AUTOSAR XML (schema 4-3-0)
package /ComponentTypes
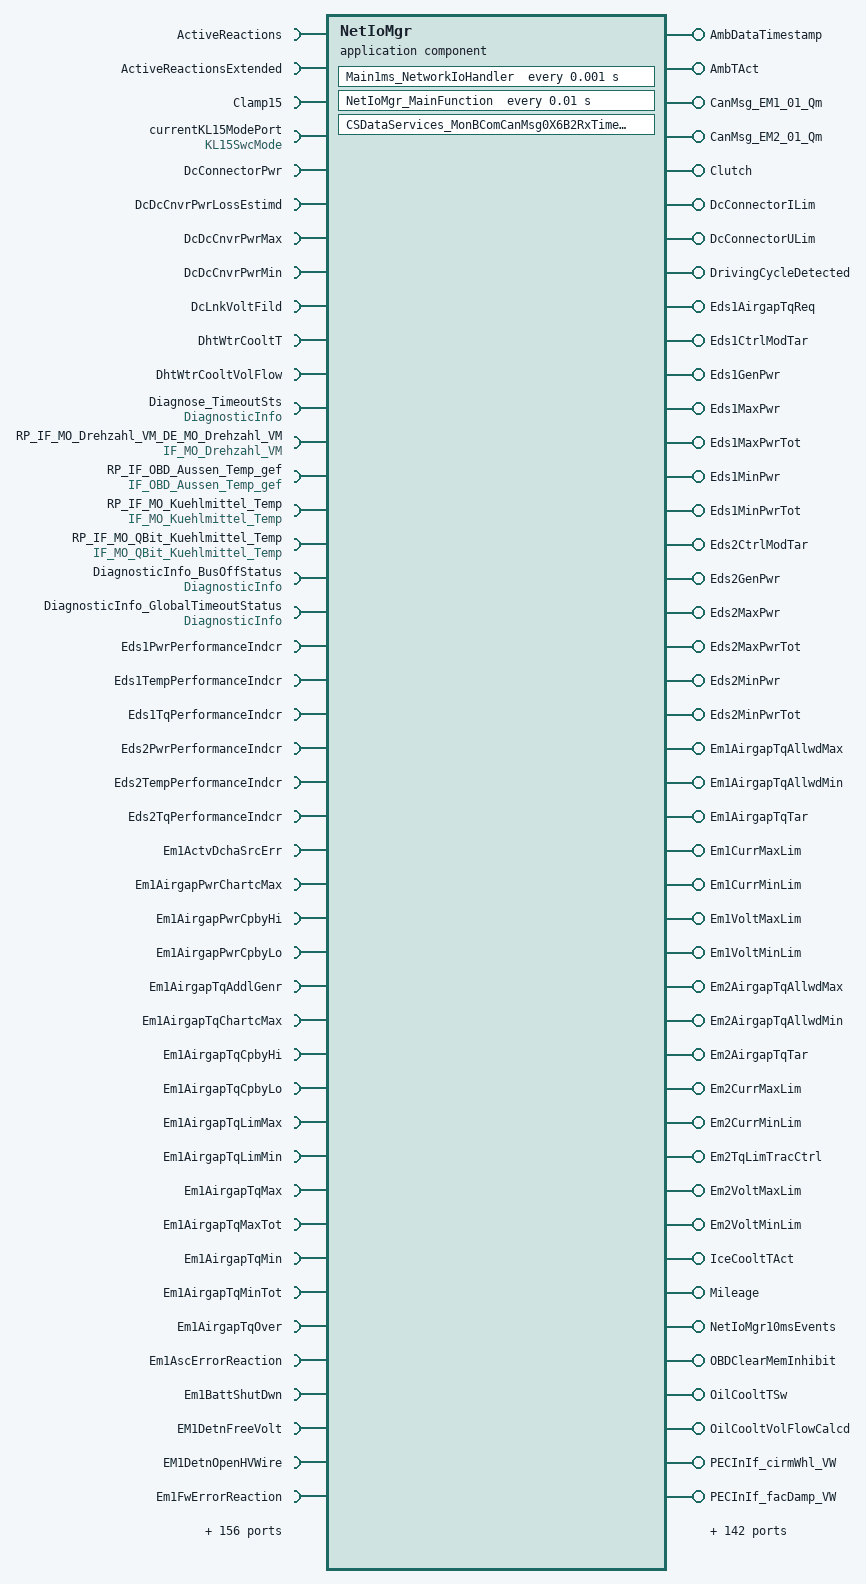
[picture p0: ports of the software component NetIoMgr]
  application sw component type NetIoMgr
    require port ActiveReactions: nonqueued-receiver-com-spec{data-element=Status, filter=data-filter-type=ALWAYS, init-value=0}, required-interface=ActiveReactions
    require port ActiveReactionsExtended: nonqueued-receiver-com-spec{data-element=Status, filter=data-filter-type=ALWAYS}, required-interface=ActiveReactionsExtended
    4 x provide port:
      AmbDataTimestamp: nonqueued-sender-com-spec{data-element=Val, init-value=fields=[UH_Jahr:0, UH_Monat:0, UH_Tag:0, UH_Stunde:0, UH_Minute:0, UH_Sekunde:0]}, provided-interface=AmbDataTimestamp
      AmbTAct: provided-com-specs=[{data-element=TVal, init-value=20 DegCgrd}, {data-element=ValSts, init-value=fields=[0 degC, 0]}], provided-interface=AmbTAct
      CanMsg_EM1_01_Qm: nonqueued-sender-com-spec=data-element=DT_SG_EM1_01, provided-interface=CanMsg_EM1_01_Qm
      CanMsg_EM2_01_Qm: nonqueued-sender-com-spec=data-element=DT_SG_EM2_01, provided-interface=CanMsg_EM2_01_Qm
    require port Clamp15: nonqueued-receiver-com-spec{data-element=ValSts, filter=data-filter-type=ALWAYS, init-value=fields=[0, 0]}, required-interface=Clamp15
    provide port Clutch: nonqueued-sender-com-spec{data-element=Sts, init-value=0}, provided-interface=Clutch
    require port currentKL15ModePort: mode-switch-receiver-com-spec=KL, required-interface=KL15SwcMode
    provide port DcConnectorILim: provided-interface=DcConnectorILim
      provided-com-specs:
        data-element=MaxIValSts, init-value=fields=[0 A, 0 A]
        data-element=MinIValSts, init-value=fields=[0 A, 0 A]
    require port DcConnectorPwr: nonqueued-receiver-com-spec{data-element=ValSts, filter=data-filter-type=ALWAYS, init-value=fields=[8190 W, 0 W]}, required-interface=DcConnectorPwr
    provide port DcConnectorULim: provided-interface=DcConnectorULim
      provided-com-specs:
        data-element=UMaxValSts, init-value=fields=[0 V, 0 V]
        data-element=UMinValSts, init-value=fields=[0 V, 0 V]
    13 x require port:
      DcDcCnvrPwrLossEstimd: required-interface=DcDcCnvrPwrLossEstimd
        required-com-specs:
          data-element=PwrVal, filter=data-filter-type=ALWAYS, init-value=0 Watt
          data-element=PwrValQf, filter=data-filter-type=ALWAYS, init-value=0
          data-element=PwrValSts, filter=data-filter-type=ALWAYS, init-value=fields=[0 W, 0]
      DcDcCnvrPwrMax: nonqueued-receiver-com-spec{data-element=ValSts, filter=data-filter-type=ALWAYS, init-value=fields=[0 W, 0]}, required-interface=DcDcCnvrPwrMax
      DcDcCnvrPwrMin: nonqueued-receiver-com-spec{data-element=ValSts, filter=data-filter-type=ALWAYS, init-value=fields=[0 W, 0]}, required-interface=DcDcCnvrPwrMin
      DcLnkVoltFild: nonqueued-receiver-com-spec{data-element=DcLnkVSts, filter=data-filter-type=ALWAYS, init-value=fields=[0 V, 0 V]}, required-interface=DcLnkVoltFild
      DhtWtrCooltT: nonqueued-receiver-com-spec{data-element=TTarValSts, filter=data-filter-type=ALWAYS, init-value=fields=[0 degC, 0 degC]}, required-interface=DhtWtrCooltT
      DhtWtrCooltVolFlow: nonqueued-receiver-com-spec{data-element=VolTarValSts, filter=data-filter-type=ALWAYS, init-value=fields=[0 lpmin, 0 lpmin]}, required-interface=DhtWtrCooltVolFlow
      Diagnose_TimeoutSts: required-interface=DiagnosticInfo
        required-com-specs:
          GetDebouncingOfEvent
          GetDTCOfEvent
          GetEventAvailable
          GetEventExtendedDataRecord
          GetEventExtendedDataRecordEx
          GetEventFailed
          GetEventFreezeFrameData
          GetEventFreezeFrameDataEx
          GetEventStatus
          GetEventTested
          GetEventUdsStatus
          GetFaultDetectionCounter
          GetMonitorStatus
      RP_IF_MO_Drehzahl_VM_DE_MO_Drehzahl_VM: nonqueued-receiver-com-spec{data-element=DE_MO_Drehzahl_VM, enable-update=true, filter=data-filter-type=ALWAYS, init-value=0}, required-interface=IF_MO_Drehzahl_VM
      RP_IF_OBD_Aussen_Temp_gef: nonqueued-receiver-com-spec{data-element=DE_OBD_Aussen_Temp_gef, enable-update=true, filter=data-filter-type=ALWAYS, init-value=254}, required-interface=IF_OBD_Aussen_Temp_gef
      RP_IF_MO_Kuehlmittel_Temp: nonqueued-receiver-com-spec{data-element=DE_MO_Kuehlmittel_Temp, enable-update=true, filter=data-filter-type=ALWAYS, init-value=254}, required-interface=IF_MO_Kuehlmittel_Temp
      RP_IF_MO_QBit_Kuehlmittel_Temp: nonqueued-receiver-com-spec{data-element=DE_MO_QBit_Kuehlmittel_Temp, filter=data-filter-type=ALWAYS, init-value=1}, required-interface=IF_MO_QBit_Kuehlmittel_Temp
      DiagnosticInfo_BusOffStatus: required-interface=DiagnosticInfo
        required-com-specs:
          GetDebouncingOfEvent
          GetDTCOfEvent
          GetEventAvailable
          GetEventExtendedDataRecord
          GetEventExtendedDataRecordEx
          GetEventFailed
          GetEventFreezeFrameData
          GetEventFreezeFrameDataEx
          GetEventStatus
          GetEventTested
          GetEventUdsStatus
          GetFaultDetectionCounter
          GetMonitorStatus
      DiagnosticInfo_GlobalTimeoutStatus: required-interface=DiagnosticInfo
        required-com-specs:
          GetDebouncingOfEvent
          GetDTCOfEvent
          GetEventAvailable
          GetEventExtendedDataRecord
          GetEventExtendedDataRecordEx
          GetEventFailed
          GetEventFreezeFrameData
          GetEventFreezeFrameDataEx
          GetEventStatus
          GetEventTested
          GetEventUdsStatus
          GetFaultDetectionCounter
          GetMonitorStatus
    8 x provide port:
      DrivingCycleDetected: nonqueued-sender-com-spec{data-element=Sts, init-value=0}, provided-interface=DrivingCycleDetected
      Eds1AirgapTqReq: nonqueued-sender-com-spec{data-element=FlgVal, init-value=0}, provided-interface=Eds1AirgapTqReq
      Eds1CtrlModTar: nonqueued-sender-com-spec{data-element=ModVal, init-value=0 State}, provided-interface=Eds1CtrlModTar
      Eds1GenPwr: nonqueued-sender-com-spec{data-element=PwrValSts, init-value=fields=[0 W, 0 W]}, provided-interface=Eds1GenPwr
      Eds1MaxPwr: nonqueued-sender-com-spec{data-element=PwrValSts, init-value=fields=[0 W, 0 W]}, provided-interface=Eds1MaxPwr
      Eds1MaxPwrTot: nonqueued-sender-com-spec{data-element=PwrValSts, init-value=fields=[0 W, 0 W]}, provided-interface=Eds1MaxPwrTot
      Eds1MinPwr: nonqueued-sender-com-spec{data-element=PwrValSts, init-value=fields=[0 W, 0 W]}, provided-interface=Eds1MinPwr
      Eds1MinPwrTot: nonqueued-sender-com-spec{data-element=PwrValSts, init-value=fields=[0 W, 0 W]}, provided-interface=Eds1MinPwrTot
    require port Eds1PwrPerformanceIndcr: nonqueued-receiver-com-spec{data-element=PwrIndcrValSts, filter=data-filter-type=ALWAYS, init-value=fields=[0 Percent, 0 Percent]}, required-interface=Eds1PwrPerformanceIndcr
    require port Eds1TempPerformanceIndcr: nonqueued-receiver-com-spec{data-element=TempIndcrValSts, filter=data-filter-type=ALWAYS, init-value=fields=[0 Percent, 0 Percent]}, required-interface=Eds1TempPerformanceIndcr
    require port Eds1TqPerformanceIndcr: nonqueued-receiver-com-spec{data-element=TqIndcrValSts, filter=data-filter-type=ALWAYS, init-value=fields=[0 Percent, 0 Percent]}, required-interface=Eds1TqPerformanceIndcr
    6 x provide port:
      Eds2CtrlModTar: nonqueued-sender-com-spec{data-element=ModVal, init-value=0 State}, provided-interface=Eds2CtrlModTar
      Eds2GenPwr: nonqueued-sender-com-spec{data-element=PwrValSts, init-value=fields=[0 W, 0 W]}, provided-interface=Eds2GenPwr
      Eds2MaxPwr: nonqueued-sender-com-spec{data-element=PwrValSts, init-value=fields=[0 W, 0 W]}, provided-interface=Eds2MaxPwr
      Eds2MaxPwrTot: nonqueued-sender-com-spec{data-element=PwrValSts, init-value=fields=[0 W, 0 W]}, provided-interface=Eds2MaxPwrTot
      Eds2MinPwr: nonqueued-sender-com-spec{data-element=PwrValSts, init-value=fields=[0 W, 0 W]}, provided-interface=Eds2MinPwr
      Eds2MinPwrTot: nonqueued-sender-com-spec{data-element=PwrValSts, init-value=fields=[0 W, 0 W]}, provided-interface=Eds2MinPwrTot
    8 x require port:
      Eds2PwrPerformanceIndcr: nonqueued-receiver-com-spec{data-element=PwrIndcrValSts, filter=data-filter-type=ALWAYS, init-value=fields=[0 Percent, 0 Percent]}, required-interface=Eds2PwrPerformanceIndcr
      Eds2TempPerformanceIndcr: nonqueued-receiver-com-spec{data-element=TempIndcrValSts, filter=data-filter-type=ALWAYS, init-value=fields=[0 Percent, 0 Percent]}, required-interface=Eds2TempPerformanceIndcr
      Eds2TqPerformanceIndcr: nonqueued-receiver-com-spec{data-element=TqIndcrValSts, filter=data-filter-type=ALWAYS, init-value=fields=[0 Percent, 0 Percent]}, required-interface=Eds2TqPerformanceIndcr
      Em1ActvDchaSrcErr: required-interface=Em1ActvDchaSrcErr
        required-com-specs:
          data-element=ErrSts, filter=data-filter-type=ALWAYS, init-value=0 B
          data-element=StsVal, filter=data-filter-type=ALWAYS, init-value=0 B
      Em1AirgapPwrChartcMax: nonqueued-receiver-com-spec{data-element=PwrMaxValSts, filter=data-filter-type=ALWAYS, init-value=fields=[0 Watt, 0 Watt]}, required-interface=Em1AirgapPwrChartcMax
      Em1AirgapPwrCpbyHi: nonqueued-receiver-com-spec{data-element=PwrValSts, filter=data-filter-type=ALWAYS, init-value=fields=[0 Watt, 0 Watt]}, required-interface=Em1AirgapPwrCpbyHi
      Em1AirgapPwrCpbyLo: nonqueued-receiver-com-spec{data-element=PwrValSts, filter=data-filter-type=ALWAYS, init-value=fields=[0 Watt, 0 Watt]}, required-interface=Em1AirgapPwrCpbyLo
      Em1AirgapTqAddlGenr: required-interface=Em1AirgapTqAddlGenr
        required-com-specs:
          data-element=TqQf, filter=data-filter-type=ALWAYS, init-value=0
          data-element=TqVal, filter=data-filter-type=ALWAYS, init-value=0 Nm
          data-element=TqValSts, filter=data-filter-type=ALWAYS, init-value=fields=[0 Nm, 0]
    provide port Em1AirgapTqAllwdMax: nonqueued-sender-com-spec{data-element=TqMaxValSts, init-value=fields=[0 Nm, 0 Nm]}, provided-interface=Em1AirgapTqAllwdMax
    provide port Em1AirgapTqAllwdMin: nonqueued-sender-com-spec{data-element=TqMinValSts, init-value=fields=[0 Nm, 0 Nm]}, provided-interface=Em1AirgapTqAllwdMin
    10 x require port:
      Em1AirgapTqChartcMax: nonqueued-receiver-com-spec{data-element=TqMaxValSts, filter=data-filter-type=ALWAYS, init-value=fields=[0 Nm, 0 Nm]}, required-interface=Em1AirgapTqChartcMax
      Em1AirgapTqCpbyHi: nonqueued-receiver-com-spec{data-element=TqValSts, filter=data-filter-type=ALWAYS, init-value=fields=[0 Nm, 0 Nm]}, required-interface=Em1AirgapTqCpbyHi
      Em1AirgapTqCpbyLo: nonqueued-receiver-com-spec{data-element=TqValSts, filter=data-filter-type=ALWAYS, init-value=fields=[0 Nm, 0 Nm]}, required-interface=Em1AirgapTqCpbyLo
      Em1AirgapTqLimMax: required-interface=Em1AirgapTqLimMax
        required-com-specs:
          data-element=TqMaxVal, filter=data-filter-type=ALWAYS, init-value=0
          data-element=TqMaxValSts, filter=data-filter-type=ALWAYS, init-value=fields=[New:0, Status:0]
      Em1AirgapTqLimMin: nonqueued-receiver-com-spec{data-element=TqMinValSts, filter=data-filter-type=ALWAYS, init-value=fields=[0 Nm, 0 Nm]}, required-interface=Em1AirgapTqLimMin
      Em1AirgapTqMax: nonqueued-receiver-com-spec{data-element=TqMaxValSts, filter=data-filter-type=ALWAYS, init-value=fields=[0 Nm, 0 Nm]}, required-interface=Em1AirgapTqMax
      Em1AirgapTqMaxTot: nonqueued-receiver-com-spec{data-element=TqMaxValSts, filter=data-filter-type=ALWAYS, init-value=fields=[0 Nm, 0 Nm]}, required-interface=Em1AirgapTqMaxTot
      Em1AirgapTqMin: nonqueued-receiver-com-spec{data-element=TqMinValSts, filter=data-filter-type=ALWAYS, init-value=fields=[0 Nm, 0 Nm]}, required-interface=Em1AirgapTqMin
      Em1AirgapTqMinTot: nonqueued-receiver-com-spec{data-element=TqMinValSts, filter=data-filter-type=ALWAYS, init-value=fields=[0 Nm, 0 Nm]}, required-interface=Em1AirgapTqMinTot
      Em1AirgapTqOver: nonqueued-receiver-com-spec{data-element=FlgVal, filter=data-filter-type=ALWAYS, init-value=0}, required-interface=Em1AirgapTqOver
    provide port Em1AirgapTqTar: nonqueued-sender-com-spec{data-element=TqValSts, init-value=fields=[0 Nm, 0 Nm]}, provided-interface=Em1AirgapTqTar
    require port Em1AscErrorReaction: nonqueued-receiver-com-spec{data-element=StsVal, filter=data-filter-type=ALWAYS, init-value=0}, required-interface=Em1AscErrorReaction
    require port Em1BattShutDwn: nonqueued-receiver-com-spec{data-element=StsVal, filter=data-filter-type=ALWAYS, init-value=0}, required-interface=Em1BattShutDwn
    provide port Em1CurrMaxLim: provided-com-specs=[{data-element=IMaxVal, init-value=0}, {data-element=IMaxValSts, init-value=fields=[0 A, 0 A]}], provided-interface=Em1CurrMaxLim
    provide port Em1CurrMinLim: provided-com-specs=[{data-element=IMinVal, init-value=0}, {data-element=IMinValSts, init-value=fields=[0 A, 0 A]}], provided-interface=Em1CurrMinLim
    11 x require port:
      EM1DetnFreeVolt: nonqueued-receiver-com-spec{data-element=StsVal, filter=data-filter-type=ALWAYS, init-value=0 State}, required-interface=EM1DetnFreeVolt
      EM1DetnOpenHVWire: nonqueued-receiver-com-spec{data-element=StsVal, filter=data-filter-type=ALWAYS, init-value=0 State}, required-interface=EM1DetnOpenHVWire
      Em1FwErrorReaction: nonqueued-receiver-com-spec{data-element=StsVal, filter=data-filter-type=ALWAYS, init-value=0}, required-interface=Em1FwErrorReaction
      Em1ParkenWfs: nonqueued-receiver-com-spec{data-element=Sts, filter=data-filter-type=ALWAYS}, required-interface=Em1ParkenWfs
      Em1RtmWarnOverCurrent: nonqueued-receiver-com-spec{data-element=Val, filter=data-filter-type=ALWAYS, init-value=0}, required-interface=Em1RtmWarnOverCurrent
      Em1RtmWarnOverSpeed: nonqueued-receiver-com-spec{data-element=Val, filter=data-filter-type=ALWAYS, init-value=0}, required-interface=Em1RtmWarnOverSpeed
      Em1RtmWarnTempEm: nonqueued-receiver-com-spec{data-element=Val, filter=data-filter-type=ALWAYS, init-value=0}, required-interface=Em1RtmWarnTempEm
      Em1RtmWarnTempPwr: nonqueued-receiver-com-spec{data-element=Val, filter=data-filter-type=ALWAYS, init-value=0}, required-interface=Em1RtmWarnTempPwr
      Em1SpdActFild: nonqueued-receiver-com-spec{data-element=SpdValSts, filter=data-filter-type=ALWAYS, init-value=fields=[0 Rpm, 0 Rpm]}, required-interface=Em1SpdActFild
      Em1SpdActvScLoInit: nonqueued-receiver-com-spec{data-element=SpdValSts, filter=data-filter-type=ALWAYS, init-value=fields=[0 Rpm, 0 Rpm]}, required-interface=Em1SpdActvScLoInit
      Em1StatorWindgTEstimd: nonqueued-receiver-com-spec{data-element=TValSts, filter=data-filter-type=ALWAYS, init-value=fields=[0 degC, 0 degC]}, required-interface=Em1StatorWindgTEstimd
    provide port Em1VoltMaxLim: provided-com-specs=[{data-element=UMaxVal, init-value=0}, {data-element=UMaxValSts, init-value=fields=[0 V, 0 V]}], provided-interface=Em1VoltMaxLim
    provide port Em1VoltMinLim: provided-com-specs=[{data-element=UMinVal, init-value=0}, {data-element=UMinValSts, init-value=fields=[0 V, 0 V]}], provided-interface=Em1VoltMinLim
    5 x require port:
      Em2ActvDchaSrcErr: required-interface=Em2ActvDchaSrcErr
        required-com-specs:
          data-element=ErrSts, filter=data-filter-type=ALWAYS, init-value=0 B
          data-element=StsVal, filter=data-filter-type=ALWAYS, init-value=0 B
      Em2AirgapPwrChartcMax: nonqueued-receiver-com-spec{data-element=PwrMaxValSts, filter=data-filter-type=ALWAYS, init-value=fields=[0 Watt, 0 Watt]}, required-interface=Em2AirgapPwrChartcMax
      Em2AirgapPwrCpbyHi: nonqueued-receiver-com-spec{data-element=PwrValSts, filter=data-filter-type=ALWAYS, init-value=fields=[0 Watt, 0 Watt]}, required-interface=Em2AirgapPwrCpbyHi
      Em2AirgapPwrCpbyLo: nonqueued-receiver-com-spec{data-element=PwrValSts, filter=data-filter-type=ALWAYS, init-value=fields=[0 Watt, 0 Watt]}, required-interface=Em2AirgapPwrCpbyLo
      Em2AirgapTqAddlGenr: nonqueued-receiver-com-spec{data-element=TqValSts, filter=data-filter-type=ALWAYS, init-value=fields=[0 Nm, 0 Nm]}, required-interface=Em2AirgapTqAddlGenr
    provide port Em2AirgapTqAllwdMax: nonqueued-sender-com-spec{data-element=TqMaxValSts, init-value=fields=[0 Nm, 0 Nm]}, provided-interface=Em2AirgapTqAllwdMax
    provide port Em2AirgapTqAllwdMin: nonqueued-sender-com-spec{data-element=TqMinValSts, init-value=fields=[0 Nm, 0 Nm]}, provided-interface=Em2AirgapTqAllwdMin
    11 x require port:
      Em2AirgapTqChartcMax: nonqueued-receiver-com-spec{data-element=TqMaxValSts, filter=data-filter-type=ALWAYS, init-value=fields=[0 Nm, 0 Nm]}, required-interface=Em2AirgapTqChartcMax
      Em2AirgapTqCpbyHi: nonqueued-receiver-com-spec{data-element=TqValSts, filter=data-filter-type=ALWAYS, init-value=fields=[0 Nm, 0 Nm]}, required-interface=Em2AirgapTqCpbyHi
      Em2AirgapTqCpbyLo: nonqueued-receiver-com-spec{data-element=TqValSts, filter=data-filter-type=ALWAYS, init-value=fields=[0 Nm, 0 Nm]}, required-interface=Em2AirgapTqCpbyLo
      Em2AirgapTqEstimd: required-com-specs=[{data-element=TqVal, filter=data-filter-type=ALWAYS, init-value=0 NwtMtr}, data-element=TqValSts], required-interface=Em2AirgapTqEstimd
      Em2AirgapTqLimMax: nonqueued-receiver-com-spec{data-element=TqMaxValSts, filter=data-filter-type=ALWAYS, init-value=fields=[0 Nm, 0 Nm]}, required-interface=Em2AirgapTqLimMax
      Em2AirgapTqLimMin: nonqueued-receiver-com-spec{data-element=TqMinValSts, filter=data-filter-type=ALWAYS, init-value=fields=[0 Nm, 0 Nm]}, required-interface=Em2AirgapTqLimMin
      Em2AirgapTqMax: nonqueued-receiver-com-spec{data-element=TqMaxValSts, filter=data-filter-type=ALWAYS, init-value=fields=[1023 Nm, 0 Nm]}, required-interface=Em2AirgapTqMax
      Em2AirgapTqMaxTot: nonqueued-receiver-com-spec{data-element=TqMaxValSts, filter=data-filter-type=ALWAYS, init-value=fields=[0 Nm, 0 Nm]}, required-interface=Em2AirgapTqMaxTot
      Em2AirgapTqMin: nonqueued-receiver-com-spec{data-element=TqMinValSts, filter=data-filter-type=ALWAYS, init-value=fields=[1023 Nm, 0 Nm]}, required-interface=Em2AirgapTqMin
      Em2AirgapTqMinTot: nonqueued-receiver-com-spec{data-element=TqMinValSts, filter=data-filter-type=ALWAYS, init-value=fields=[0 Nm, 0 Nm]}, required-interface=Em2AirgapTqMinTot
      Em2AirgapTqOver: nonqueued-receiver-com-spec{data-element=FlgVal, filter=data-filter-type=ALWAYS, init-value=0}, required-interface=Em2AirgapTqOver
    provide port Em2AirgapTqTar: provided-com-specs=[{data-element=TqVal, init-value=0 NwtMtr}, {data-element=TqValSts, init-value=fields=[0 Nm, 0 Nm]}], provided-interface=Em2AirgapTqTar
    require port Em2AscErrorReaction: nonqueued-receiver-com-spec{data-element=StsVal, filter=data-filter-type=ALWAYS, init-value=0}, required-interface=Em2AscErrorReaction
    require port Em2BattShutDwn: nonqueued-receiver-com-spec{data-element=StsVal, filter=data-filter-type=ALWAYS, init-value=0}, required-interface=Em2BattShutDwn
    provide port Em2CurrMaxLim: provided-com-specs=[{data-element=IMaxVal, init-value=0}, {data-element=IMaxValSts, init-value=fields=[0 A, 0 A]}], provided-interface=Em2CurrMaxLim
    provide port Em2CurrMinLim: provided-com-specs=[{data-element=IMinVal, init-value=0}, {data-element=IMinValSts, init-value=fields=[0 A, 0 A]}], provided-interface=Em2CurrMinLim
    11 x require port:
      EM2DetnFreeVolt: nonqueued-receiver-com-spec{data-element=StsVal, filter=data-filter-type=ALWAYS, init-value=0 State}, required-interface=EM2DetnFreeVolt
      EM2DetnOpenHVWire: nonqueued-receiver-com-spec{data-element=StsVal, filter=data-filter-type=ALWAYS, init-value=0 State}, required-interface=EM2DetnOpenHVWire
      Em2FwErrorReaction: nonqueued-receiver-com-spec{data-element=StsVal, filter=data-filter-type=ALWAYS, init-value=0}, required-interface=Em2FwErrorReaction
      Em2RtmWarnOverCurrent: nonqueued-receiver-com-spec{data-element=Val, filter=data-filter-type=ALWAYS, init-value=0}, required-interface=Em2RtmWarnOverCurrent
      Em2RtmWarnOverSpeed: nonqueued-receiver-com-spec{data-element=Val, filter=data-filter-type=ALWAYS, init-value=0}, required-interface=Em2RtmWarnOverSpeed
      Em2RtmWarnTempEm: nonqueued-receiver-com-spec{data-element=Val, filter=data-filter-type=ALWAYS, init-value=0}, required-interface=Em2RtmWarnTempEm
      Em2RtmWarnTempPwr: nonqueued-receiver-com-spec{data-element=Val, filter=data-filter-type=ALWAYS, init-value=0}, required-interface=Em2RtmWarnTempPwr
      Em2SpdAct: required-interface=Em2SpdAct
        required-com-specs:
          data-element=SpdQf, filter=data-filter-type=ALWAYS, init-value=0
          data-element=SpdVal, filter=data-filter-type=ALWAYS, init-value=0 Rpm
      Em2SpdActFild: nonqueued-receiver-com-spec{data-element=SpdValSts, filter=data-filter-type=ALWAYS, init-value=fields=[0 Rpm, 0 Rpm]}, required-interface=Em2SpdActFild
      Em2SpdActvScLoInit: nonqueued-receiver-com-spec{data-element=SpdValSts, filter=data-filter-type=ALWAYS, init-value=fields=[0 Rpm, 0 Rpm]}, required-interface=Em2SpdActvScLoInit
      Em2StatorWindgTEstimd: nonqueued-receiver-com-spec{data-element=TValSts, filter=data-filter-type=ALWAYS, init-value=fields=[0 degC, 0 degC]}, required-interface=Em2StatorWindgTEstimd
    provide port Em2TqLimTracCtrl: provided-com-specs=[{data-element=TqMaxVal, init-value=0 Nm}, {data-element=TqMinVal, init-value=0 Nm}], provided-interface=Em2TqLimTracCtrl
    provide port Em2VoltMaxLim: provided-com-specs=[{data-element=UMaxVal, init-value=0}, {data-element=UMaxValSts, init-value=fields=[0 A, 0 A]}], provided-interface=Em2VoltMaxLim
    provide port Em2VoltMinLim: provided-com-specs=[{data-element=UMinVal, init-value=0}, {data-element=UMinValSts, init-value=fields=[0 V, 0 V]}], provided-interface=Em2VoltMinLim
    require port HeatExWtrCooltOutlT: nonqueued-receiver-com-spec{data-element=TValSts, filter=data-filter-type=ALWAYS, init-value=fields=[20 degC, 0 degC]}, required-interface=HeatExWtrCooltOutlT
    provide port IceCooltTAct: provided-com-specs=[{data-element=TVal, init-value=0 degC}, {data-element=ValSts, init-value=fields=[0 degC, 0]}], provided-interface=IceCooltTAct
    4 x require port:
      InsMonError: nonqueued-receiver-com-spec{data-element=StsVal, filter=data-filter-type=ALWAYS, init-value=1 State}, required-interface=InsMonError
      InsMonState: required-interface=InsMonState
        required-com-specs:
          data-element=ErrSts, init-value=0 State
          data-element=Sts, filter=data-filter-type=ALWAYS, init-value=0 State
      KL30_OverVoltage: mode-switch-receiver-com-spec=VoltageMonitorMode, required-interface=IF_VoltageMonitorMode
      KL30_UnderVoltage: mode-switch-receiver-com-spec=VoltageMonitorMode, required-interface=IF_VoltageMonitorMode
    provide port Mileage: nonqueued-sender-com-spec{data-element=ValSts, init-value=fields=[New:1048574, Status:0]}, provided-interface=Mileage
    require port NDCPe1CtrlCddCurr: required-interface=NDCPe1CtrlCddCurr
      required-com-specs:
        data-element=IdcVal, filter=data-filter-type=ALWAYS, init-value=0 Ampere
        data-element=IdcValSts, filter=data-filter-type=ALWAYS, init-value=fields=[0 A, 0 A]
    require port NDCPe2CtrlCddCurr: required-interface=NDCPe2CtrlCddCurr
      required-com-specs:
        data-element=IdcVal, filter=data-filter-type=ALWAYS, init-value=0 Ampere
        data-element=IdcValSts, filter=data-filter-type=ALWAYS, init-value=fields=[0 A, 0 A]
    provide port NetIoMgr10msEvents: nonqueued-sender-com-spec{data-element=Status, init-value=35 x 255}, provided-interface=NetIoMgr10msEvents
    provide port OBDClearMemInhibit: nonqueued-sender-com-spec{data-element=FlgVal, init-value=0}, provided-interface=OBDClearMemInhibit
    require port OBDLampReq: nonqueued-receiver-com-spec{data-element=Sts, filter=data-filter-type=ALWAYS, init-value=0}, required-interface=OBDLampReq
    provide port OilCooltTSw: nonqueued-sender-com-spec{data-element=TValSts, init-value=fields=[0 degC, 0 degC]}, provided-interface=OilCooltTSw
    provide port OilCooltVolFlowCalcd: nonqueued-sender-com-spec{data-element=VolFlowValSts, init-value=fields=[0 lpmin, 0 lpmin]}, provided-interface=OilCooltVolFlowCalcd
    require port Pe1Energies: nonqueued-receiver-com-spec{data-element=Val, filter=data-filter-type=ALWAYS}, required-interface=Pe1Energies
    require port Pe2Energies: nonqueued-receiver-com-spec{data-element=Val, filter=data-filter-type=ALWAYS}, required-interface=Pe2Energies
    12 x provide port:
      PECInIf_cirmWhl_VW: nonqueued-sender-com-spec{data-element=PECInIf_cirmWhl_VW, init-value=0}, provided-interface=PECInIf_cirmWhl_VW
      PECInIf_facDamp_VW: nonqueued-sender-com-spec{data-element=PECInIf_facDamp_VW, init-value=0}, provided-interface=PECInIf_facDamp_VW
      PECInIf_nMax_VW: nonqueued-sender-com-spec{data-element=PECInIf_nMax_VW, init-value=0}, provided-interface=PECInIf_nMax_VW
      PECInIf_nMin_VW: nonqueued-sender-com-spec{data-element=PECInIf_nMin_VW, init-value=0}, provided-interface=PECInIf_nMin_VW
      PECInIf_noToothWhlSens_VW: nonqueued-sender-com-spec{data-element=PECInIf_noToothWhlSens_VW, init-value=0}, provided-interface=PECInIf_noToothWhlSens_VW
      PECInIf_stClu_VW: nonqueued-sender-com-spec{data-element=PECInIf_stClu_VW, init-value=0}, provided-interface=PECInIf_stClu_VW
      PECInIf_stCluAvl_VW: nonqueued-sender-com-spec{data-element=PECInIf_stCluAvl_VW, init-value=0}, provided-interface=PECInIf_stCluAvl_VW
      PECInIf_stReqDampCtl_VW: nonqueued-sender-com-spec{data-element=PECInIf_stReqDampCtl_VW, init-value=0}, provided-interface=PECInIf_stReqDampCtl_VW
      PECInIf_tqDampThd_VW: nonqueued-sender-com-spec{data-element=PECInIf_tqDampThd_VW, init-value=0}, provided-interface=PECInIf_tqDampThd_VW
      PECInIf_tqSp_VW: nonqueued-sender-com-spec{data-element=PECInIf_tqSp_VW, init-value=0}, provided-interface=PECInIf_tqSp_VW
      PECInIf_vWhlFrntLe_VW: nonqueued-sender-com-spec{data-element=PECInIf_vWhlFrntLe_VW, init-value=0}, provided-interface=PECInIf_vWhlFrntLe_VW
      PECInIf_vWhlFrntRi_VW: nonqueued-sender-com-spec{data-element=PECInIf_vWhlFrntRi_VW, init-value=0}, provided-interface=PECInIf_vWhlFrntRi_VW
    7 x require port:
      PECOutIf_bDampCtl_VW: nonqueued-receiver-com-spec{data-element=PECOutIf_bDampCtl_VW, filter=data-filter-type=ALWAYS, init-value=0}, required-interface=PECOutIf_bDampCtl_VW
      PECOutIf_nWhlAbsLe_VW: nonqueued-receiver-com-spec{data-element=PECOutIf_nWhlAbsLe_VW, filter=data-filter-type=ALWAYS, init-value=0}, required-interface=PECOutIf_nWhlAbsLe_VW
      PECOutIf_nWhlAbsRi_VW: nonqueued-receiver-com-spec{data-element=PECOutIf_nWhlAbsRi_VW, filter=data-filter-type=ALWAYS, init-value=0}, required-interface=PECOutIf_nWhlAbsRi_VW
      PECOutIf_stSpdlCtl_VW: nonqueued-receiver-com-spec{data-element=PECOutIf_stSpdlCtl_VW, filter=data-filter-type=ALWAYS, init-value=0}, required-interface=PECOutIf_stSpdlCtl_VW
      PECOutIf_tqDamp_VW: nonqueued-receiver-com-spec{data-element=PECOutIf_tqDamp_VW, filter=data-filter-type=ALWAYS, init-value=0}, required-interface=PECOutIf_tqDamp_VW
      PECOutIf_tqSpSpdl_VW: nonqueued-receiver-com-spec{data-element=PECOutIf_tqSpSpdl_VW, filter=data-filter-type=ALWAYS, init-value=0}, required-interface=PECOutIf_tqSpSpdl_VW
      PeWtrCooltOutlTEstimd: required-interface=PeWtrCooltOutlTEstimd
        required-com-specs:
          data-element=TVal, filter=data-filter-type=ALWAYS, init-value=20 degC
          data-element=TValQf, filter=data-filter-type=ALWAYS, init-value=0
    4 x provide port:
      PP_DrvgRdy: nonqueued-sender-com-spec=data-element=Sts, provided-interface=DrvgRdy
      ProductionModeActv: nonqueued-sender-com-spec{data-element=Sts, init-value=0}, provided-interface=ProductionModeActv
      ProductionModeValid: nonqueued-sender-com-spec{data-element=Sts, init-value=0}, provided-interface=ProductionModeValid
      RlySts: nonqueued-sender-com-spec{data-element=StsVal, init-value=0}, provided-interface=RlySts
    98 x require port:
      RP_Em1BlockingInfoWfs: nonqueued-receiver-com-spec{data-element=StsVal, filter=data-filter-type=ALWAYS, init-value=0}, required-interface=Em1BlockingInfoWfs
      RP_Em1ReleaseExpInfoWfs: nonqueued-receiver-com-spec{data-element=StsVal, filter=data-filter-type=ALWAYS, init-value=0}, required-interface=Em1ReleaseExpInfoWfs
      RP_Em1ReleaseInfoWfs: nonqueued-receiver-com-spec{data-element=StsVal, filter=data-filter-type=ALWAYS, init-value=0}, required-interface=Em1ReleaseInfoWfs
      RP_IF_BR_QBit_Reifenumfang_XIX_Grundumfang_XIX_LE_TWIN: nonqueued-receiver-com-spec{data-element=DE_BR_QBit_Reifenumfang, init-value=0}, required-interface=IF_BR_QBit_Reifenumfang
      RP_IF_BR_Reifenumfang_XIX_Grundumfang_XIX_LE_TWIN: nonqueued-receiver-com-spec{data-element=DE_BR_Reifenumfang, init-value=0}, required-interface=IF_BR_Reifenumfang
      RP_IF_CluEng_Avl_XIX_Grundumfang_XIX_LE_TWIN: nonqueued-receiver-com-spec{data-element=DE_CluEng_Avl, filter=data-filter-type=ALWAYS, init-value=0}, required-interface=IF_CluEng_Avl
      RP_IF_CluEng_State_XIX_Grundumfang_XIX_LE_TWIN: nonqueued-receiver-com-spec{data-element=DE_CluEng_State, enable-update=true, filter=data-filter-type=ALWAYS, init-value=0}, required-interface=IF_CluEng_State
      RP_IF_ESP_VL_Radgeschw_02_XIX_Grundumfang_XIX_LE_TWIN: nonqueued-receiver-com-spec{data-element=DE_ESP_VL_Radgeschw_02, enable-update=true, init-value=0}, required-interface=IF_ESP_VL_Radgeschw_02
      RP_IF_ESP_VR_Radgeschw_02_XIX_Grundumfang_XIX_LE_TWIN: nonqueued-receiver-com-spec{data-element=DE_ESP_VR_Radgeschw_02, enable-update=true, init-value=0}, required-interface=IF_ESP_VR_Radgeschw_02
      RP_IF_ESP_Zaehnezahl_XIX_Grundumfang_XIX_LE_TWIN: nonqueued-receiver-com-spec{data-element=DE_ESP_Zaehnezahl, enable-update=true, init-value=0}, required-interface=IF_ESP_Zaehnezahl
      RP_IF_eTM_Pumpe1_Status_XIX_Grundumfang_XIX_LE_TWIN: nonqueued-receiver-com-spec{data-element=DE_eTM_Pumpe1_Status, enable-update=true, init-value=0}, required-interface=IF_eTM_Pumpe1_Status
      RP_IF_eTM_Pumpe1_Volumenstrom_XIX_Grundumfang_XIX_LE_TWIN: nonqueued-receiver-com-spec{data-element=DE_eTM_Pumpe1_Volumenstrom, enable-update=true, init-value=62}, required-interface=IF_eTM_Pumpe1_Volumenstrom
      RP_IF_eTM_Pumpe1_Volumenstromteilung_XIX_Grundumfang_XIX_LE_TWIN: nonqueued-receiver-com-spec{data-element=DE_eTM_Pumpe1_Volumenstromteilung, init-value=0}, required-interface=IF_eTM_Pumpe1_Volumenstromteilung
      RP_IF_eTM_Pumpe2_Status_XIX_Grundumfang_XIX_LE_TWIN: nonqueued-receiver-com-spec{data-element=DE_eTM_Pumpe2_Status, init-value=0}, required-interface=IF_eTM_Pumpe2_Status
      RP_IF_eTM_Pumpe2_Volumenstrom_XIX_Grundumfang_XIX_LE_TWIN: nonqueued-receiver-com-spec{data-element=DE_eTM_Pumpe2_Volumenstrom, init-value=0}, required-interface=IF_eTM_Pumpe2_Volumenstrom
      RP_IF_eTM_Pumpe3_Status_XIX_Grundumfang_XIX_LE_TWIN: nonqueued-receiver-com-spec{data-element=DE_eTM_Pumpe3_Status, init-value=0}, required-interface=IF_eTM_Pumpe3_Status
      RP_IF_eTM_Temperatur_1_XIX_Grundumfang_XIX_LE_TWIN: nonqueued-receiver-com-spec{data-element=DE_eTM_Temperatur_1, init-value=254}, required-interface=IF_eTM_Temperatur_1
      RP_IF_eTM_Temperatur_2_XIX_Grundumfang_XIX_LE_TWIN: nonqueued-receiver-com-spec{data-element=DE_eTM_Temperatur_2, init-value=0}, required-interface=IF_eTM_Temperatur_2
      RP_IF_ImoCord_Auth_Aufforderung_WFS_XIX_Grundumfang_XIX_LE_TWIN: nonqueued-receiver-com-spec{data-element=DE_ImoCord_Auth_Aufforderung_WFS, enable-update=true, init-value=0}, required-interface=IF_ImoCord_Auth_Aufforderung_WFS
      RP_IF_KBI_Kilometerstand_XIX_Grundumfang_XIX_LE_TWIN: nonqueued-receiver-com-spec{data-element=DE_KBI_Kilometerstand, enable-update=true, init-value=0}, required-interface=IF_KBI_Kilometerstand
      RP_IF_KST_Sonderzustand_Status_XIX_Grundumfang_XIX_LE_TWIN: nonqueued-receiver-com-spec{data-element=DE_KST_Sonderzustand_Status, enable-update=true, init-value=0}, required-interface=IF_KST_Sonderzustand_Status
      RP_IF_KST_WFS_Fahrfreigabe_Anforderung_XIX_Grundumfang_XIX_LE_TWIN: nonqueued-receiver-com-spec{data-element=DE_KST_WFS_Fahrfreigabe_Anforderung, init-value=0}, required-interface=IF_KST_WFS_Fahrfreigabe_Anforderung
      RP_IF_LCU_IstOelVolumenstrom_XIX_Grundumfang_XIX_LE_TWIN: nonqueued-receiver-com-spec{data-element=DE_LCU_IstOelVolumenstrom, enable-update=true, filter=data-filter-type=ALWAYS, init-value=0}, required-interface=IF_LCU_IstOelVolumenstrom
      RP_IF_LCU_OelTempPlausi_XIX_Grundumfang_XIX_LE_TWIN: nonqueued-receiver-com-spec{data-element=DE_LCU_OelTempPlausi, enable-update=true, filter=data-filter-type=ALWAYS, init-value=0}, required-interface=IF_LCU_OelTempPlausi
      RP_IF_MO_Drehzahl_01_XIX_Grundumfang_XIX_LE_TWIN: nonqueued-receiver-com-spec{data-element=DE_MO_Drehzahl_01, init-value=0}, required-interface=IF_MO_Drehzahl_01
      RP_IF_MO_EM1_Generator_Leistung_XIX_Grundumfang_XIX_LE_TWIN: nonqueued-receiver-com-spec{data-element=DE_MO_EM1_Generator_Leistung, enable-update=true, init-value=0}, required-interface=IF_MO_EM1_Generator_Leistung
      RP_IF_MO_EM1_Max_Leistung_Gesamt_XIX_Grundumfang_XIX_LE_TWIN: nonqueued-receiver-com-spec{data-element=DE_MO_EM1_Max_Leistung_Gesamt, init-value=0}, required-interface=IF_MO_EM1_Max_Leistung_Gesamt
      RP_IF_MO_EM1_Max_Spannung_Lim_XIX_Grundumfang_XIX_LE_TWIN: nonqueued-receiver-com-spec{data-element=DE_MO_EM1_Max_Spannung_Lim, enable-update=true, filter=data-filter-type=ALWAYS}, required-interface=IF_MO_EM1_Max_Spannung_Lim
      RP_IF_MO_EM1_Min_Leistung_Gesamt_XIX_Grundumfang_XIX_LE_TWIN: nonqueued-receiver-com-spec{data-element=DE_MO_EM1_Min_Leistung_Gesamt, init-value=0}, required-interface=IF_MO_EM1_Min_Leistung_Gesamt
      RP_IF_MO_EM1_Min_Spannung_Lim_XIX_Grundumfang_XIX_LE_TWIN: nonqueued-receiver-com-spec{data-element=DE_MO_EM1_Min_Spannung_Lim, enable-update=true, filter=data-filter-type=ALWAYS}, required-interface=IF_MO_EM1_Min_Spannung_Lim
      RP_IF_MO_EM2_Generator_Leistung_XIX_Grundumfang_XIX_LE_TWIN: nonqueued-receiver-com-spec{data-element=DE_MO_EM2_Generator_Leistung, enable-update=true, init-value=0}, required-interface=IF_MO_EM2_Generator_Leistung
      RP_IF_MO_EM2_Max_Leistung_Gesamt_XIX_Grundumfang_XIX_LE_TWIN: nonqueued-receiver-com-spec{data-element=DE_MO_EM2_Max_Leistung_Gesamt, init-value=0}, required-interface=IF_MO_EM2_Max_Leistung_Gesamt
      RP_IF_MO_EM2_Max_Spannung_Lim_XIX_Grundumfang_XIX_LE_TWIN: nonqueued-receiver-com-spec{data-element=DE_MO_EM2_Max_Spannung_Lim, enable-update=true, filter=data-filter-type=ALWAYS}, required-interface=IF_MO_EM2_Max_Spannung_Lim
      RP_IF_MO_EM2_Min_Leistung_Gesamt_XIX_Grundumfang_XIX_LE_TWIN: nonqueued-receiver-com-spec{data-element=DE_MO_EM2_Min_Leistung_Gesamt, init-value=0}, required-interface=IF_MO_EM2_Min_Leistung_Gesamt
      RP_IF_MO_EM2_Min_Spannung_Lim_XIX_Grundumfang_XIX_LE_TWIN: nonqueued-receiver-com-spec{data-element=DE_MO_EM2_Min_Spannung_Lim, enable-update=true, filter=data-filter-type=ALWAYS}, required-interface=IF_MO_EM2_Min_Spannung_Lim
      RP_IF_MO_ErwGrenzen_Anf_XIX_Grundumfang_XIX_LE_TWIN: nonqueued-receiver-com-spec{data-element=DE_MO_ErwGrenzen_Anf, enable-update=true, init-value=0}, required-interface=IF_MO_ErwGrenzen_Anf
      RP_IF_MO_Fahrbereitschaft_XIX_Grundumfang_XIX_LE_TWIN: nonqueued-receiver-com-spec{data-element=DE_MO_Fahrbereitschaft, enable-update=true, init-value=0}, required-interface=IF_MO_Fahrbereitschaft
      RP_IF_MO_Fahrzeugabstellzeit_Status_XIX_Grundumfang_XIX_LE_TWIN: nonqueued-receiver-com-spec{data-element=DE_MO_Fahrzeugabstellzeit_Status, init-value=0}, required-interface=IF_MO_Fahrzeugabstellzeit_Status
      RP_IF_MO_Fahrzeugabstellzeit_XIX_Grundumfang_XIX_LE_TWIN: nonqueued-receiver-com-spec{data-element=DE_MO_Fahrzeugabstellzeit, enable-update=true, init-value=0}, required-interface=IF_MO_Fahrzeugabstellzeit
      RP_IF_MO_HV_Auszeit_Status_XIX_Grundumfang_XIX_LE_TWIN: nonqueued-receiver-com-spec{data-element=DE_MO_HV_Auszeit_Status, init-value=0}, required-interface=IF_MO_HV_Auszeit_Status
      RP_IF_MO_HV_Auszeit_XIX_Grundumfang_XIX_LE_TWIN: nonqueued-receiver-com-spec{data-element=DE_MO_HV_Auszeit, enable-update=true, init-value=0}, required-interface=IF_MO_HV_Auszeit
      RP_IF_MO_OBD_Typ_XIX_Grundumfang_XIX_LE_TWIN: nonqueued-receiver-com-spec{data-element=DE_MO_OBD_Typ, init-value=0}, required-interface=IF_MO_OBD_Typ
      RP_IF_MO_TNW_Max_Spannung_Lim_XIX_Grundumfang_XIX_LE_TWIN: nonqueued-receiver-com-spec{data-element=DE_MO_TNW_Max_Spannung_Lim, init-value=1022}, required-interface=IF_MO_TNW_Max_Spannung_Lim
      RP_IF_MO_TNW_Max_Strom_Lim_XIX_Grundumfang_XIX_LE_TWIN: nonqueued-receiver-com-spec{data-element=DE_MO_TNW_Max_Strom_Lim, enable-update=true, init-value=8190}, required-interface=IF_MO_TNW_Max_Strom_Lim
      RP_IF_MO_TNW_Min_Spannung_Lim_XIX_Grundumfang_XIX_LE_TWIN: nonqueued-receiver-com-spec{data-element=DE_MO_TNW_Min_Spannung_Lim, init-value=1022}, required-interface=IF_MO_TNW_Min_Spannung_Lim
      RP_IF_MO_TNW_Min_Strom_Lim_XIX_Grundumfang_XIX_LE_TWIN: nonqueued-receiver-com-spec{data-element=DE_MO_TNW_Min_Strom_Lim, init-value=8190}, required-interface=IF_MO_TNW_Min_Strom_Lim
      RP_IF_OBD_Abs_Pedal_Pos_XIX_Grundumfang_XIX_LE_TWIN: nonqueued-receiver-com-spec{data-element=DE_OBD_Abs_Pedal_Pos, init-value=0}, required-interface=IF_OBD_Abs_Pedal_Pos
      RP_IF_OBD_Calc_Load_Val_XIX_Grundumfang_XIX_LE_TWIN: nonqueued-receiver-com-spec{data-element=DE_OBD_Calc_Load_Val, init-value=0}, required-interface=IF_OBD_Calc_Load_Val
      RP_IF_OBD_ClearMem_Inhibit_XIX_Grundumfang_XIX_LE_TWIN: nonqueued-receiver-com-spec{data-element=DE_OBD_ClearMem_Inhibit, init-value=0}, required-interface=IF_OBD_ClearMem_Inhibit
      RP_IF_OBD_Driving_Cycle_XIX_Grundumfang_XIX_LE_TWIN: nonqueued-receiver-com-spec{data-element=DE_OBD_Driving_Cycle, init-value=0}, required-interface=IF_OBD_Driving_Cycle
      RP_IF_OBD_Kaltstart_Denominator_XIX_Grundumfang_XIX_LE_TWIN: nonqueued-receiver-com-spec{data-element=DE_OBD_Kaltstart_Denominator, init-value=0}, required-interface=IF_OBD_Kaltstart_Denominator
      RP_IF_OBD_Normed_Trip_XIX_Grundumfang_XIX_LE_TWIN: nonqueued-receiver-com-spec{data-element=DE_OBD_Normed_Trip, init-value=0}, required-interface=IF_OBD_Normed_Trip
      RP_IF_OBD_Sperrung_IUMPR_XIX_Grundumfang_XIX_LE_TWIN: nonqueued-receiver-com-spec{data-element=DE_OBD_Sperrung_IUMPR, init-value=0}, required-interface=IF_OBD_Sperrung_IUMPR
      RP_IF_OBD_Sperrung_Kaltstart_Denom_XIX_Grundumfang_XIX_LE_TWIN: nonqueued-receiver-com-spec{data-element=DE_OBD_Sperrung_Kaltstart_Denom, init-value=0}, required-interface=IF_OBD_Sperrung_Kaltstart_Denom
      RP_IF_OBD_Warm_Up_Cycle_XIX_Grundumfang_XIX_LE_TWIN: nonqueued-receiver-com-spec{data-element=DE_OBD_Warm_Up_Cycle, init-value=0}, required-interface=IF_OBD_Warm_Up_Cycle
      RP_IF_OBDProtocol_req_XIX_Grundumfang_XIX_LE_TWIN: nonqueued-receiver-com-spec{data-element=DE_OBDProtocol_req, enable-update=true, filter=data-filter-type=ALWAYS}, required-interface=IF_OBDProtocol_req
      RP_IF_SG_Airbag_01: nonqueued-receiver-com-spec{data-element=SG_Airbag_01, enable-update=true, filter=data-filter-type=ALWAYS, init-value=fields=[ElementConstant:0, ElementConstant_1:0, ElementConstant_2:0, ElementConstant_3:8, ElementConstant_4:0, ElementConstant_5:0, ElementConstant_6:0, ElementConstant_7:1, ElementConstant_8:0, ElementConstant_9:1, ElementConstant_10:0, ElementConstant_11:0, ElementConstant_12:0, ElementConstant_13:0, ElementConstant_14:0, ElementConstant_15:0, ElementConstant_16:1, ElementConstant_17:0, ElementConstant_18:1, ElementConstant_19:0, ElementConstant_20:1, ElementConstant_21:0, ElementConstant_22:0, ElementConstant_23:0, ElementConstant_24:0, ElementConstant_25:0, ElementConstant_26:0, ElementConstant_27:6, ElementConstant_28:0, ElementConstant_29:0, ElementConstant_30:0, ElementConstant_31:255]}, required-interface=IF_SG_Airbag_01
      RP_IF_SG_ESP_21: nonqueued-receiver-com-spec{data-element=SG_ESP_21, enable-update=true, filter=data-filter-type=ALWAYS, init-value=fields=[ElementConstant:0, ElementConstant_1:0, ElementConstant_2:1022, ElementConstant_3:0, ElementConstant_4:0, ElementConstant_5:0, ElementConstant_6:6, ElementConstant_7:0, ElementConstant_8:0, ElementConstant_9:0, ElementConstant_10:1, ElementConstant_11:65534, ElementConstant_12:0, ElementConstant_13:0, ElementConstant_14:0, ElementConstant_15:0, ElementConstant_16:0, ElementConstant_17:0, ElementConstant_18:1, ElementConstant_19:0, ElementConstant_20:0, ElementConstant_21:0, ElementConstant_22:0, ElementConstant_23:0, ElementConstant_24:0, ElementConstant_25:0, ElementConstant_26:0]}, required-interface=IF_SG_ESP_21
      RP_IF_SG_HVK_01: nonqueued-receiver-com-spec{data-element=SG_HVK_01, enable-update=true, filter=data-filter-type=ALWAYS, init-value=fields=[ElementConstant:0, ElementConstant_1:0, ElementConstant_2:0, ElementConstant_3:3, ElementConstant_4:0, ElementConstant_5:0, ElementConstant_6:7, ElementConstant_7:7, ElementConstant_8:7, ElementConstant_9:7, ElementConstant_10:7, ElementConstant_11:0, ElementConstant_12:0, ElementConstant_13:0, ElementConstant_14:0, ElementConstant_15:0, ElementConstant_16:2, ElementConstant_17:0, ElementConstant_18:0, ElementConstant_19:0, ElementConstant_20:3, ElementConstant_21:0]}, required-interface=IF_SG_HVK_01
      RP_IF_SG_Klemmen_Status_01: nonqueued-receiver-com-spec{data-element=SG_Klemmen_Status_01, enable-update=true, filter=data-filter-type=ALWAYS, init-value=fields=[ElementConstant:0, ElementConstant_1:0, ElementConstant_2:0, ElementConstant_3:0, ElementConstant_4:0, ElementConstant_5:0, ElementConstant_6:0, ElementConstant_7:0, ElementConstant_8:0, ElementConstant_9:0, ElementConstant_10:0, ElementConstant_11:0, ElementConstant_12:0, ElementConstant_13:0, ElementConstant_14:0, ElementConstant_15:0, ElementConstant_16:0, ElementConstant_17:0, ElementConstant_18:0]}, required-interface=IF_SG_Klemmen_Status_01
      RP_IF_SG_Motor_56: nonqueued-receiver-com-spec{data-element=SG_Motor_56, enable-update=true, filter=data-filter-type=ALWAYS, init-value=fields=[ElementConstant:0, ElementConstant_1:0, ElementConstant_2:16383, ElementConstant_3:16383, ElementConstant_4:255, ElementConstant_5:255, ElementConstant_6:4094, ElementConstant_7:8190, ElementConstant_8:15, ElementConstant_9:8190, ElementConstant_10:16382, ElementConstant_11:0, ElementConstant_12:511, ElementConstant_13:0, ElementConstant_14:16382, ElementConstant_15:0, ElementConstant_16:4095, ElementConstant_17:255, ElementConstant_18:16383, ElementConstant_19:255, ElementConstant_20:15, ElementConstant_21:16382, ElementConstant_22:16382, ElementConstant_23:0, ElementConstant_24:511, ElementConstant_25:16383, ElementConstant_26:8190, ElementConstant_27:4094, ElementConstant_28:8190, ElementConstant_29:4094, ElementConstant_30:4094, ElementConstant_31:4095, ElementConstant_32:0, ElementConstant_33:4094, ElementConstant_34:255, ElementConstant_35:255, ElementConstant_36:4094]}, required-interface=IF_SG_Motor_56
      RP_IF_SI_P_Mode_gueltig_XIX_Grundumfang_XIX_LE_TWIN: nonqueued-receiver-com-spec{data-element=DE_SI_P_Mode_gueltig, init-value=0}, required-interface=IF_SI_P_Mode_gueltig
      RP_IF_SI_P_Mode_XIX_Grundumfang_XIX_LE_TWIN: nonqueued-receiver-com-spec{data-element=DE_SI_P_Mode, init-value=0}, required-interface=IF_SI_P_Mode
      RP_IF_UH_Jahr_XIX_Grundumfang_XIX_LE_TWIN: nonqueued-receiver-com-spec{data-element=DE_UH_Jahr, init-value=0}, required-interface=IF_UH_Jahr
      RP_IF_UH_Minute_XIX_Grundumfang_XIX_LE_TWIN: nonqueued-receiver-com-spec{data-element=DE_UH_Minute, init-value=0}, required-interface=IF_UH_Minute
      RP_IF_UH_Monat_XIX_Grundumfang_XIX_LE_TWIN: nonqueued-receiver-com-spec{data-element=DE_UH_Monat, init-value=0}, required-interface=IF_UH_Monat
      RP_IF_UH_Sekunde_XIX_Grundumfang_XIX_LE_TWIN: nonqueued-receiver-com-spec{data-element=DE_UH_Sekunde, init-value=0}, required-interface=IF_UH_Sekunde
      RP_IF_UH_Stunde_XIX_Grundumfang_XIX_LE_TWIN: nonqueued-receiver-com-spec{data-element=DE_UH_Stunde, init-value=0}, required-interface=IF_UH_Stunde
      RP_IF_UH_Tag_XIX_Grundumfang_XIX_LE_TWIN: nonqueued-receiver-com-spec{data-element=DE_UH_Tag, init-value=0}, required-interface=IF_UH_Tag
      RP_IF_VIN_01_MUX0x{00..02}: nonqueued-receiver-com-spec{data-element=DE_VIN_01_MUX, enable-update=true, filter=data-filter-type=ALWAYS}, required-interface=IF_VIN_01_MUX
      RP_IF_VIN_1: nonqueued-receiver-com-spec{data-element=DE_VIN_1, filter=data-filter-type=ALWAYS, init-value=45}, required-interface=IF_VIN_1
      RP_IF_VIN_{10..17}: nonqueued-receiver-com-spec{data-element=DE_VIN_{10..17}, filter=data-filter-type=ALWAYS, init-value=45}, required-interface=IF_VIN_{10..17}
      RP_IF_VIN_{2..9}: nonqueued-receiver-com-spec{data-element=DE_VIN_{2..9}, filter=data-filter-type=ALWAYS, init-value=45}, required-interface=IF_VIN_{2..9}
      RP_IF_WFS_IMMO_MSG4_CRC_XIX_Grundumfang_XIX_LE_TWIN: nonqueued-receiver-com-spec{data-element=DE_WFS_IMMO_MSG4_CRC, init-value=0}, required-interface=IF_WFS_IMMO_MSG4_CRC
      RP_IF_WFS_IMMO_MSG4_Data_0_XIX_Grundumfang_XIX_LE_TWIN: nonqueued-receiver-com-spec{data-element=DE_WFS_IMMO_MSG4_Data_0, enable-update=true, init-value=0}, required-interface=IF_WFS_IMMO_MSG4_Data_0
      RP_IF_WFS_IMMO_MSG4_Data_1_XIX_Grundumfang_XIX_LE_TWIN: nonqueued-receiver-com-spec{data-element=DE_WFS_IMMO_MSG4_Data_1, init-value=0}, required-interface=IF_WFS_IMMO_MSG4_Data_1
      RP_IF_WFS_IMMO_MSG4_Data_2_XIX_Grundumfang_XIX_LE_TWIN: nonqueued-receiver-com-spec{data-element=DE_WFS_IMMO_MSG4_Data_2, init-value=0}, required-interface=IF_WFS_IMMO_MSG4_Data_2
      RP_IF_WFS_IMMO_MSG4_Status_XIX_Grundumfang_XIX_LE_TWIN: nonqueued-receiver-com-spec{data-element=DE_WFS_IMMO_MSG4_Status, init-value=0}, required-interface=IF_WFS_IMMO_MSG4_Status
      RP_WfsInquiryCrc: nonqueued-receiver-com-spec{data-element=Val, filter=data-filter-type=ALWAYS, init-value=0}, required-interface=WfsInquiryCrc
      RP_WfsInquiryRnd: nonqueued-receiver-com-spec{data-element=Val, enable-update=true, filter=data-filter-type=ALWAYS, init-value=0}, required-interface=WfsInquiryRnd
      ServiceReq: nonqueued-receiver-com-spec{data-element=Sts, filter=data-filter-type=ALWAYS, init-value=0}, required-interface=ServiceReq
      SmpOilTEstimd: nonqueued-receiver-com-spec{data-element=TValSts, init-value=fields=[0 degC, 0 degC]}, required-interface=SmpOilTEstimd
    107 x provide port:
      SP_DrivePermissionRequest: nonqueued-sender-com-spec{data-element=Val, init-value=0}, provided-interface=DrivePermissionRequest
      SP_IF_EM1_AktiveEntladung_XIX_Grundumfang_XIX_LE_TWIN: nonqueued-sender-com-spec{data-element=DE_EM1_AktiveEntladung, init-value=0}, provided-interface=IF_EM1_AktiveEntladung
      SP_IF_EM1_AnlernenElMotor_Anf_XIX_Grundumfang_XIX_LE_TWIN: nonqueued-sender-com-spec{data-element=DE_EM1_AnlernenElMotor_Anf, init-value=0}, provided-interface=IF_EM1_AnlernenElMotor_Anf
      SP_IF_EM1_EM_SollVolumenstrom: nonqueued-sender-com-spec{data-element=DE_EM1_EM_SollVolumenstrom, init-value=0}, provided-interface=IF_EM1_EM_SollVolumenstrom
      SP_IF_EM1_Fehler_AE_XIX_Grundumfang_XIX_LE_TWIN: nonqueued-sender-com-spec{data-element=DE_EM1_Fehler_AE, init-value=0}, provided-interface=IF_EM1_Fehler_AE
      SP_IF_EM1_Fehler_ElAntriebFreilauf_XIX_Grundumfang_XIX_LE_TWIN: nonqueued-sender-com-spec{data-element=DE_EM1_Fehler_ElAntriebFreilauf, init-value=0}, provided-interface=IF_EM1_Fehler_ElAntriebFreilauf
      SP_IF_EM1_Fehler_Leistungsred: nonqueued-sender-com-spec{data-element=DE_EM1_Fehler_Leistungsred, init-value=0}, provided-interface=IF_EM1_Fehler_Leistungsred
      SP_IF_EM1_Fehlerlampe_Anf_XIX_Grundumfang_XIX_LE_TWIN: nonqueued-sender-com-spec{data-element=DE_EM1_Fehlerlampe_Anf, init-value=0}, provided-interface=IF_EM1_Fehlerlampe_Anf
      SP_IF_EM1_Freigabe_Info_WFS_XIX_Grundumfang_XIX_LE_TWIN: nonqueued-sender-com-spec{data-element=DE_EM1_Freigabe_Info_WFS, init-value=0}, provided-interface=IF_EM1_Freigabe_Info_WFS
      SP_IF_EM1_Freigabe_Verfallsinfo_WFS_XIX_Grundumfang_XIX_LE_TWIN: nonqueued-sender-com-spec{data-element=DE_EM1_Freigabe_Verfallsinfo_WFS, init-value=0}, provided-interface=IF_EM1_Freigabe_Verfallsinfo_WFS
      SP_IF_EM1_Generator_Moment_XIX_Grundumfang_XIX_LE_TWIN: nonqueued-sender-com-spec{data-element=DE_EM1_Generator_Moment, init-value=0}, provided-interface=IF_EM1_Generator_Moment
      SP_IF_EM1_IsoFehler_XIX_Grundumfang_XIX_LE_TWIN: nonqueued-sender-com-spec{data-element=DE_EM1_IsoFehler, init-value=0}, provided-interface=IF_EM1_IsoFehler
      SP_IF_EM1_IsoZustand_XIX_Grundumfang_XIX_LE_TWIN: nonqueued-sender-com-spec{data-element=DE_EM1_IsoZustand, init-value=0}, provided-interface=IF_EM1_IsoZustand
      SP_IF_EM1_IstStrom: nonqueued-sender-com-spec{data-element=DE_EM1_IstStrom, init-value=0}, provided-interface=IF_EM1_IstStrom
      SP_IF_EM1_Kuehlung_EM_Anf_02_XIX_Grundumfang_XIX_LE_TWIN: nonqueued-sender-com-spec=data-element=DE_EM1_Kuehlung_EM_Anf_02, provided-interface=IF_EM1_Kuehlung_EM_Anf_02
      SP_IF_EM1_Max_LeistungMech_Sockel_XIX_Grundumfang_XIX_LE_TWIN: nonqueued-sender-com-spec{data-element=DE_EM1_Max_LeistungMech_Sockel, init-value=0}, provided-interface=IF_EM1_Max_LeistungMech_Sockel
      SP_IF_EM1_Max_MechLeistung_nom_XIX_Grundumfang_XIX_LE_TWIN: nonqueued-sender-com-spec{data-element=DE_EM1_Max_MechLeistung_nom, init-value=0}, provided-interface=IF_EM1_Max_MechLeistung_nom
      SP_IF_EM1_Max_Moment_nom_XIX_Grundumfang_XIX_LE_TWIN: nonqueued-sender-com-spec{data-element=DE_EM1_Max_Moment_nom, init-value=0}, provided-interface=IF_EM1_Max_Moment_nom
      SP_IF_EM1_Max_Moment_Sockel_XIX_Grundumfang_XIX_LE_TWIN: nonqueued-sender-com-spec{data-element=DE_EM1_Max_Moment_Sockel, init-value=0}, provided-interface=IF_EM1_Max_Moment_Sockel
      SP_IF_EM1_MaxZul_Drehzahl_XIX_Grundumfang_XIX_LE_TWIN: nonqueued-sender-com-spec{data-element=DE_EM1_MaxZul_Drehzahl, init-value=0}, provided-interface=IF_EM1_MaxZul_Drehzahl
      SP_IF_EM1_Min_LeistungMech_Sockel_XIX_Grundumfang_XIX_LE_TWIN: nonqueued-sender-com-spec{data-element=DE_EM1_Min_LeistungMech_Sockel, init-value=0}, provided-interface=IF_EM1_Min_LeistungMech_Sockel
      SP_IF_EM1_Min_Moment_Sockel_XIX_Grundumfang_XIX_LE_TWIN: nonqueued-sender-com-spec{data-element=DE_EM1_Min_Moment_Sockel, init-value=0}, provided-interface=IF_EM1_Min_Moment_Sockel
      SP_IF_EM1_OBD_Lampe_Anf_XIX_Grundumfang_XIX_LE_TWIN: nonqueued-sender-com-spec{data-element=DE_EM1_OBD_Lampe_Anf, init-value=0}, provided-interface=IF_EM1_OBD_Lampe_Anf
      SP_IF_EM1_Parken_WFS_Status_XIX_Grundumfang_XIX_LE_TWIN: nonqueued-sender-com-spec{data-element=DE_EM1_Parken_WFS_Status, init-value=0}, provided-interface=IF_EM1_Parken_WFS_Status
      SP_IF_EM1_PerfInd_MaxLeistung_XIX_Grundumfang_XIX_LE_TWIN: nonqueued-sender-com-spec{data-element=DE_EM1_PerfInd_MaxLeistung, init-value=0}, provided-interface=IF_EM1_PerfInd_MaxLeistung
      SP_IF_EM1_PerfInd_MaxMoment_XIX_Grundumfang_XIX_LE_TWIN: nonqueued-sender-com-spec{data-element=DE_EM1_PerfInd_MaxMoment, init-value=0}, provided-interface=IF_EM1_PerfInd_MaxMoment
      SP_IF_EM1_PerfInd_Temperatur_XIX_Grundumfang_XIX_LE_TWIN: nonqueued-sender-com-spec{data-element=DE_EM1_PerfInd_Temperatur, init-value=0}, provided-interface=IF_EM1_PerfInd_Temperatur
      SP_IF_EM1_PWR_SollVolumenstrom_XIX_Grundumfang_XIX_LE_TWIN: nonqueued-sender-com-spec{data-element=DE_EM1_PWR_SollVolumenstrom, init-value=0}, provided-interface=IF_EM1_PWR_SollVolumenstrom
      SP_IF_EM1_Rekuperation_Ueberlauf_XIX_Grundumfang_XIX_LE_TWIN: nonqueued-sender-com-spec{data-element=DE_EM1_Rekuperation_Ueberlauf, init-value=0}, provided-interface=IF_EM1_Rekuperation_Ueberlauf
      SP_IF_EM1_Rekuperation_XIX_Grundumfang_XIX_LE_TWIN: nonqueued-sender-com-spec{data-element=DE_EM1_Rekuperation, init-value=0}, provided-interface=IF_EM1_Rekuperation
      SP_IF_EM1_RtmWarnTempEM_XIX_Grundumfang_XIX_LE_TWIN: nonqueued-sender-com-spec{data-element=DE_EM1_RtmWarnTempEM, init-value=0}, provided-interface=IF_EM1_RtmWarnTempEM
      SP_IF_EM1_RtmWarnTempPWR_XIX_Grundumfang_XIX_LE_TWIN: nonqueued-sender-com-spec{data-element=DE_EM1_RtmWarnTempPWR, init-value=0}, provided-interface=IF_EM1_RtmWarnTempPWR
      SP_IF_EM1_RtmWarnUeberdrehzahl_XIX_Grundumfang_XIX_LE_TWIN: nonqueued-sender-com-spec{data-element=DE_EM1_RtmWarnUeberdrehzahl, init-value=0}, provided-interface=IF_EM1_RtmWarnUeberdrehzahl
      SP_IF_EM1_RtmWarnUeberstrom_XIX_Grundumfang_XIX_LE_TWIN: nonqueued-sender-com-spec{data-element=DE_EM1_RtmWarnUeberstrom, init-value=0}, provided-interface=IF_EM1_RtmWarnUeberstrom
      SP_IF_EM1_SmpOilTEstimd_XIX_Grundumfang_XIX_LE_TWIN: nonqueued-sender-com-spec=data-element=DE_EM1_SmpOilTEstimd, provided-interface=IF_EM1_SmpOilTEstimd
      SP_IF_EM1_SollOelVolumenstrom: nonqueued-sender-com-spec{data-element=DE_EM1_SollOelVolumenstrom, init-value=0}, provided-interface=IF_EM1_SollOelVolumenstrom
      SP_IF_EM1_SollVorlauftemperatur_XIX_Grundumfang_XIX_LE_TWIN: nonqueued-sender-com-spec{data-element=DE_EM1_SollVorlauftemperatur, init-value=0}, provided-interface=IF_EM1_SollVorlauftemperatur
      SP_IF_EM1_Sperr_Info_WFS_XIX_Grundumfang_XIX_LE_TWIN: nonqueued-sender-com-spec{data-element=DE_EM1_Sperr_Info_WFS, init-value=0}, provided-interface=IF_EM1_Sperr_Info_WFS
      SP_IF_EM1_Status_EoHVL_XIX_Grundumfang_XIX_LE_TWIN: nonqueued-sender-com-spec{data-element=DE_EM1_Status_EoHVL, init-value=0}, provided-interface=IF_EM1_Status_EoHVL
      SP_IF_EM1_Status_Spgfreiheit_XIX_Grundumfang_XIX_LE_TWIN: nonqueued-sender-com-spec{data-element=DE_EM1_Status_Spgfreiheit, init-value=0}, provided-interface=IF_EM1_Status_Spgfreiheit
      SP_IF_EM1_Temperatur_EM: nonqueued-sender-com-spec{data-element=DE_EM1_Temperatur_EM, init-value=0}, provided-interface=IF_EM1_Temperatur_EM
      SP_IF_EM1_Temperatur_PWR_XIX_Grundumfang_XIX_LE_TWIN: nonqueued-sender-com-spec{data-element=DE_EM1_Temperatur_PWR, init-value=0}, provided-interface=IF_EM1_Temperatur_PWR
      SP_IF_EM1_Verbrauch_Ueberlauf_XIX_Grundumfang_XIX_LE_TWIN: nonqueued-sender-com-spec{data-element=DE_EM1_Verbrauch_Ueberlauf, init-value=0}, provided-interface=IF_EM1_Verbrauch_Ueberlauf
      SP_IF_EM1_Verbrauch_XIX_Grundumfang_XIX_LE_TWIN: nonqueued-sender-com-spec{data-element=DE_EM1_Verbrauch, init-value=0}, provided-interface=IF_EM1_Verbrauch
      SP_IF_EM1_Warnlampe_Anf_XIX_Grundumfang_XIX_LE_TWIN: nonqueued-sender-com-spec{data-element=DE_EM1_Warnlampe_Anf, init-value=0}, provided-interface=IF_EM1_Warnlampe_Anf
      SP_IF_EM2_AktiveEntladung: nonqueued-sender-com-spec{data-element=DE_EM2_AktiveEntladung, init-value=0}, provided-interface=IF_EM2_AktiveEntladung
      SP_IF_EM2_AnlernenElMotor_Anf_XIX_Grundumfang_XIX_LE_TWIN: nonqueued-sender-com-spec{data-element=DE_EM2_AnlernenElMotor_Anf, init-value=0}, provided-interface=IF_EM2_AnlernenElMotor_Anf
      SP_IF_EM2_AR_aktiv_XIX_Grundumfang_XIX_LE_TWIN: nonqueued-sender-com-spec{data-element=DE_EM2_AR_aktiv, init-value=0}, provided-interface=IF_EM2_AR_aktiv
      SP_IF_EM2_EM_SollVolumenstrom: nonqueued-sender-com-spec{data-element=DE_EM2_EM_SollVolumenstrom, init-value=0}, provided-interface=IF_EM2_EM_SollVolumenstrom
      SP_IF_EM2_Fehler_AE: nonqueued-sender-com-spec{data-element=DE_EM2_Fehler_AE, init-value=0}, provided-interface=IF_EM2_Fehler_AE
      SP_IF_EM2_Fehler_ElAntriebFreilauf_XIX_Grundumfang_XIX_LE_TWIN: nonqueued-sender-com-spec{data-element=DE_EM2_Fehler_ElAntriebFreilauf, init-value=0}, provided-interface=IF_EM2_Fehler_ElAntriebFreilauf
      SP_IF_EM2_Fehler_Leistungsred: nonqueued-sender-com-spec{data-element=DE_EM2_Fehler_Leistungsred, init-value=0}, provided-interface=IF_EM2_Fehler_Leistungsred
      SP_IF_EM2_Fehlerlampe_Anf_XIX_Grundumfang_XIX_LE_TWIN: nonqueued-sender-com-spec{data-element=DE_EM2_Fehlerlampe_Anf, init-value=0}, provided-interface=IF_EM2_Fehlerlampe_Anf
      SP_IF_EM2_Generator_Moment_XIX_Grundumfang_XIX_LE_TWIN: nonqueued-sender-com-spec{data-element=DE_EM2_Generator_Moment, init-value=0}, provided-interface=IF_EM2_Generator_Moment
      SP_IF_EM2_Max_LeistungMech_Sockel: nonqueued-sender-com-spec{data-element=DE_EM2_Max_LeistungMech_Sockel, init-value=0}, provided-interface=IF_EM2_Max_LeistungMech_Sockel
      SP_IF_EM2_Max_MechLeistung_nom_XIX_Grundumfang_XIX_LE_TWIN: nonqueued-sender-com-spec{data-element=DE_EM2_Max_MechLeistung_nom, init-value=0}, provided-interface=IF_EM2_Max_MechLeistung_nom
      SP_IF_EM2_Max_Moment_nom_XIX_Grundumfang_XIX_LE_TWIN: nonqueued-sender-com-spec{data-element=DE_EM2_Max_Moment_nom, init-value=0}, provided-interface=IF_EM2_Max_Moment_nom
      SP_IF_EM2_Max_Moment_Sockel: nonqueued-sender-com-spec{data-element=DE_EM2_Max_Moment_Sockel, init-value=0}, provided-interface=IF_EM2_Max_Moment_Sockel
      SP_IF_EM2_MaxZul_Drehzahl_XIX_Grundumfang_XIX_LE_TWIN: nonqueued-sender-com-spec{data-element=DE_EM2_MaxZul_Drehzahl, init-value=0}, provided-interface=IF_EM2_MaxZul_Drehzahl
      SP_IF_EM2_Min_LeistungMech_Sockel: nonqueued-sender-com-spec{data-element=DE_EM2_Min_LeistungMech_Sockel, init-value=0}, provided-interface=IF_EM2_Min_LeistungMech_Sockel
      SP_IF_EM2_Min_Moment_Sockel: nonqueued-sender-com-spec{data-element=DE_EM2_Min_Moment_Sockel, init-value=0}, provided-interface=IF_EM2_Min_Moment_Sockel
      SP_IF_EM2_OBD_Lampe_Anf_XIX_Grundumfang_XIX_LE_TWIN: nonqueued-sender-com-spec{data-element=DE_EM2_OBD_Lampe_Anf, init-value=0}, provided-interface=IF_EM2_OBD_Lampe_Anf
      SP_IF_EM2_PerfInd_MaxLeistung_XIX_Grundumfang_XIX_LE_TWIN: nonqueued-sender-com-spec{data-element=DE_EM2_PerfInd_MaxLeistung, init-value=0}, provided-interface=IF_EM2_PerfInd_MaxLeistung
      SP_IF_EM2_PerfInd_MaxMoment_XIX_Grundumfang_XIX_LE_TWIN: nonqueued-sender-com-spec{data-element=DE_EM2_PerfInd_MaxMoment, init-value=0}, provided-interface=IF_EM2_PerfInd_MaxMoment
      SP_IF_EM2_PerfInd_Temperatur_XIX_Grundumfang_XIX_LE_TWIN: nonqueued-sender-com-spec{data-element=DE_EM2_PerfInd_Temperatur, init-value=0}, provided-interface=IF_EM2_PerfInd_Temperatur
      SP_IF_EM2_PWR_SollVolumenstrom_XIX_Grundumfang_XIX_LE_TWIN: nonqueued-sender-com-spec{data-element=DE_EM2_PWR_SollVolumenstrom, init-value=0}, provided-interface=IF_EM2_PWR_SollVolumenstrom
      SP_IF_EM2_Rekuperation_Ueberlauf_XIX_Grundumfang_XIX_LE_TWIN: nonqueued-sender-com-spec{data-element=DE_EM2_Rekuperation_Ueberlauf, init-value=0}, provided-interface=IF_EM2_Rekuperation_Ueberlauf
      SP_IF_EM2_Rekuperation_XIX_Grundumfang_XIX_LE_TWIN: nonqueued-sender-com-spec{data-element=DE_EM2_Rekuperation, init-value=0}, provided-interface=IF_EM2_Rekuperation
      SP_IF_EM2_RtmWarnTempEM_XIX_Grundumfang_XIX_LE_TWIN: nonqueued-sender-com-spec{data-element=DE_EM2_RtmWarnTempEM, init-value=0}, provided-interface=IF_EM2_RtmWarnTempEM
      SP_IF_EM2_RtmWarnTempPWR_XIX_Grundumfang_XIX_LE_TWIN: nonqueued-sender-com-spec{data-element=DE_EM2_RtmWarnTempPWR, init-value=0}, provided-interface=IF_EM2_RtmWarnTempPWR
      SP_IF_EM2_RtmWarnUeberdrehzahl_XIX_Grundumfang_XIX_LE_TWIN: nonqueued-sender-com-spec{data-element=DE_EM2_RtmWarnUeberdrehzahl, init-value=0}, provided-interface=IF_EM2_RtmWarnUeberdrehzahl
      SP_IF_EM2_RtmWarnUeberstrom_XIX_Grundumfang_XIX_LE_TWIN: nonqueued-sender-com-spec{data-element=DE_EM2_RtmWarnUeberstrom, init-value=0}, provided-interface=IF_EM2_RtmWarnUeberstrom
      SP_IF_EM2_SollVorlauftemperatur_XIX_Grundumfang_XIX_LE_TWIN: nonqueued-sender-com-spec{data-element=DE_EM2_SollVorlauftemperatur, init-value=0}, provided-interface=IF_EM2_SollVorlauftemperatur
      SP_IF_EM2_Status_EoHVL: nonqueued-sender-com-spec{data-element=DE_EM2_Status_EoHVL, init-value=0}, provided-interface=IF_EM2_Status_EoHVL
      SP_IF_EM2_Status_Spgfreiheit: nonqueued-sender-com-spec{data-element=DE_EM2_Status_Spgfreiheit, init-value=0}, provided-interface=IF_EM2_Status_Spgfreiheit
      SP_IF_EM2_Temperatur_EM: nonqueued-sender-com-spec{data-element=DE_EM2_Temperatur_EM, init-value=0}, provided-interface=IF_EM2_Temperatur_EM
      SP_IF_EM2_Temperatur_PWR_XIX_Grundumfang_XIX_LE_TWIN: nonqueued-sender-com-spec{data-element=DE_EM2_Temperatur_PWR, init-value=0}, provided-interface=IF_EM2_Temperatur_PWR
      SP_IF_EM2_Verbrauch_Ueberlauf_XIX_Grundumfang_XIX_LE_TWIN: nonqueued-sender-com-spec{data-element=DE_EM2_Verbrauch_Ueberlauf, init-value=0}, provided-interface=IF_EM2_Verbrauch_Ueberlauf
      SP_IF_EM2_Verbrauch_XIX_Grundumfang_XIX_LE_TWIN: nonqueued-sender-com-spec{data-element=DE_EM2_Verbrauch, init-value=0}, provided-interface=IF_EM2_Verbrauch
      SP_IF_EM2_Warnlampe_Anf_XIX_Grundumfang_XIX_LE_TWIN: nonqueued-sender-com-spec{data-element=DE_EM2_Warnlampe_Anf, init-value=0}, provided-interface=IF_EM2_Warnlampe_Anf
      SP_IF_EMotor_01_Abschaltstufe_XIX_Grundumfang_XIX_LE_TWIN: nonqueued-sender-com-spec{data-element=DE_EMotor_01_Abschaltstufe, init-value=0}, provided-interface=IF_EMotor_01_Abschaltstufe
      SP_IF_EMotor_01_KD_Fehler_XIX_Grundumfang_XIX_LE_TWIN: nonqueued-sender-com-spec{data-element=DE_EMotor_01_KD_Fehler, init-value=0}, provided-interface=IF_EMotor_01_KD_Fehler
      SP_IF_EMotor_01_Transport_Mode_XIX_Grundumfang_XIX_LE_TWIN: nonqueued-sender-com-spec{data-element=DE_EMotor_01_Transport_Mode, init-value=0}, provided-interface=IF_EMotor_01_Transport_Mode
      SP_IF_KN_EMotor_01_BusKnockOut_XIX_Grundumfang_XIX_LE_TWIN: nonqueued-sender-com-spec{data-element=DE_KN_EMotor_01_BusKnockOut, init-value=0}, provided-interface=IF_KN_EMotor_01_BusKnockOut
      SP_IF_KN_EMotor_01_BusKnockOutTimer_XIX_Grundumfang_XIX_LE_TWIN: nonqueued-sender-com-spec{data-element=DE_KN_EMotor_01_BusKnockOutTimer, init-value=0}, provided-interface=IF_KN_EMotor_01_BusKnockOutTimer
      SP_IF_KN_EMotor_01_ECUKnockOut_XIX_Grundumfang_XIX_LE_TWIN: nonqueued-sender-com-spec{data-element=DE_KN_EMotor_01_ECUKnockOut, init-value=0}, provided-interface=IF_KN_EMotor_01_ECUKnockOut
      SP_IF_KN_EMotor_01_ECUKnockOutTimer_XIX_Grundumfang_XIX_LE_TWIN: nonqueued-sender-com-spec{data-element=DE_KN_EMotor_01_ECUKnockOutTimer, init-value=0}, provided-interface=IF_KN_EMotor_01_ECUKnockOutTimer
      SP_IF_LE1_Indc_StChk_XIX_Grundumfang_XIX_LE_TWIN: nonqueued-sender-com-spec=data-element=DE_LE1_Indc_StChk, provided-interface=IF_LE1_Indc_StChk
      SP_IF_LE1_Indc_StFail_XIX_Grundumfang_XIX_LE_TWIN: nonqueued-sender-com-spec=data-element=DE_LE1_Indc_StFail, provided-interface=IF_LE1_Indc_StFail
      SP_IF_NM_EM1_01_CBV_AWB_XIX_Grundumfang_XIX_LE_TWIN: nonqueued-sender-com-spec{data-element=DE_NM_EMotor_01_CBV_AWB, init-value=0}, provided-interface=IF_NM_EMotor_01_CBV_AWB
      SP_IF_NM_EMotor_01_Wakeup_XIX_Grundumfang_XIX_LE_TWIN: nonqueued-sender-com-spec{data-element=DE_NM_EMotor_01_Wakeup, init-value=0}, provided-interface=IF_NM_EMotor_01_Wakeup
      SP_IF_OBDProtocol_LE1_XIX_Grundumfang_XIX_LE_TWIN: nonqueued-sender-com-spec=data-element=DE_OBDProtocol_LE1, provided-interface=IF_OBDProtocol_LE1
      SP_IF_SG_EM1_01: nonqueued-sender-com-spec=data-element=SG_EM1_01, provided-interface=IF_SG_EM1_01
      SP_IF_SG_EM2_01: nonqueued-sender-com-spec{data-element=SG_EM2_01, init-value=fields=[ElementConstant:0, ElementConstant_1:0, ElementConstant_2:15, ElementConstant_3:4094, ElementConstant_4:4094, ElementConstant_5:32766, ElementConstant_6:0, ElementConstant_7:4094, ElementConstant_8:4094, ElementConstant_9:2046, ElementConstant_10:0, ElementConstant_11:2046, ElementConstant_12:0, ElementConstant_13:2046, ElementConstant_14:0, ElementConstant_15:2046, ElementConstant_16:0, ElementConstant_17:2046, ElementConstant_18:8190, ElementConstant_19:8190, ElementConstant_20:2046, ElementConstant_21:2046, ElementConstant_22:0, ElementConstant_23:0, ElementConstant_24:0, ElementConstant_25:0, ElementConstant_26:0, ElementConstant_27:0, ElementConstant_28:0, ElementConstant_29:0, ElementConstant_30:0, ElementConstant_31:0]}, provided-interface=IF_SG_EM2_01
      SP_IF_TNW_IstLeistung_Prim_XIX_Grundumfang_XIX_LE_TWIN: nonqueued-sender-com-spec{data-element=DE_TNW_IstLeistung_Prim, init-value=8190}, provided-interface=IF_TNW_IstLeistung_Prim
      SP_IF_TNW_Max_Leistung_XIX_Grundumfang_XIX_LE_TWIN: nonqueued-sender-com-spec{data-element=DE_TNW_Max_Leistung, init-value=0}, provided-interface=IF_TNW_Max_Leistung
      SP_IF_TNW_Min_Leistung: nonqueued-sender-com-spec{data-element=DE_TNW_Min_Leistung, init-value=2046}, provided-interface=IF_TNW_Min_Leistung
      SP_IF_TNW_VerlustLeistung_XIX_Grundumfang_XIX_LE_TWIN: nonqueued-sender-com-spec{data-element=DE_TNW_VerlustLeistung, init-value=0}, provided-interface=IF_TNW_VerlustLeistung
      SP_IF_WFS_MSG4_CRC_XIX_Grundumfang_XIX_LE_TWIN: nonqueued-sender-com-spec{data-element=DE_WFS_MSG4_CRC, init-value=0}, provided-interface=IF_WFS_MSG4_CRC
      SP_IF_WFS_MSG4_RND_XIX_Grundumfang_XIX_LE_TWIN: nonqueued-sender-com-spec{data-element=DE_WFS_MSG4_RND, init-value=0}, provided-interface=IF_WFS_MSG4_RND
      SP_IfVinMux: provided-com-specs=[{data-element=Sts, init-value=0}, {data-element=VinVal, init-value=17 x 0}], provided-interface=IfVinMux
      SP_ImoCordAuthPromptWfs: nonqueued-sender-com-spec{data-element=StsVal, init-value=0}, provided-interface=ImoCordAuthPromptWfs
      SP_KL15TranSt: nonqueued-sender-com-spec{data-element=Sts, init-value=0}, provided-interface=KL15TranSt
      SP_ObdAccrPedalPos: nonqueued-sender-com-spec=data-element=ValSts, provided-interface=ObdAccrPedalPos
      SP_ObdCalcLoad: nonqueued-sender-com-spec=data-element=ValSts, provided-interface=ObdCalcLoad
      SP_SpecialState: nonqueued-sender-com-spec{data-element=Val, init-value=0}, provided-interface=SpecialState
      SP_WfsImmoMsg4: provided-interface=WfsImmoMsg4
        provided-com-specs:
          data-element=CrcVal, init-value=0
          data-element=D{0..3}Val, init-value=0
          data-element=StsVal, init-value=0
    require port TOilCooltVolFlow: nonqueued-receiver-com-spec{data-element=VolTarValSts, filter=data-filter-type=ALWAYS, init-value=fields=[0 lpmin, 0 lpmin]}, required-interface=TOilCooltVolFlow
    provide port ToothNr: nonqueued-sender-com-spec{data-element=NrVal, init-value=0}, provided-interface=ToothNr
    provide port VehTiOff: nonqueued-sender-com-spec{data-element=TiValSts, init-value=fields=[0 min, 0 min]}, provided-interface=VehTiOff
    provide port VehVAct: provided-interface=VehVAct
      provided-com-specs:
        data-element=QBit, init-value=0
        data-element=ValSts, init-value=fields=[0 kmph, 0]
        data-element=VVal, init-value=0 kmph
    require port Vtg_EnableCondition: client-com-spec=SetEnableCondition, required-interface=EnableCondition
    6 x provide port:
      WarmUpCycleDetected: nonqueued-sender-com-spec{data-element=Sts, init-value=0}, provided-interface=WarmUpCycleDetected
      WtrCoolt: nonqueued-sender-com-spec{data-element=StsVal, init-value=0 State}, provided-interface=WtrCoolt
      WtrCooltInlTAct: nonqueued-sender-com-spec{data-element=TVal, init-value=20 DegCgrd}, provided-interface=WtrCooltInlTAct
      WtrCooltInlVolFlowAct: provided-interface=WtrCooltInlVolFlowAct
        provided-com-specs:
          data-element=ValSts, init-value=fields=[0 lpmin, 0 lpmin]
          data-element=VolVal, init-value=0 lppermin
      ObdNormTrip: nonqueued-sender-com-spec{data-element=FlgVal, init-value=0}, provided-interface=ObdNormTrip
      ObdSperrung: nonqueued-sender-com-spec{data-element=FlgVal, init-value=0}, provided-interface=ObdSperrung
    4 x require port:
      CANNodeECUKnockOut: nonqueued-receiver-com-spec{data-element=Sts, filter=data-filter-type=ALWAYS, init-value=0}, required-interface=CANNodeECUKnockOut
      CANNodeECUKnockOutTimer: nonqueued-receiver-com-spec{data-element=Val, filter=data-filter-type=ALWAYS, init-value=0}, required-interface=CANNodeECUKnockOutTimer
      CANNodeBusKnockOut: nonqueued-receiver-com-spec{data-element=Sts, filter=data-filter-type=ALWAYS, init-value=0}, required-interface=CANNodeBusKnockOut
      CANNodeBusKnockOutTimer: nonqueued-receiver-com-spec{data-element=Val, filter=data-filter-type=ALWAYS, init-value=0}, required-interface=CANNodeBusKnockOutTimer
    4 x provide port:
      Em1EffDegrLoadMin: nonqueued-sender-com-spec{data-element=Val, init-value=0}, provided-interface=Em1EffDegrLoadMin
      EngSpd: nonqueued-sender-com-spec{data-element=ValSts, init-value=fields=[New:0, Status:0]}, provided-interface=EngSpd
      OBDSperrungKaltstartDenom: nonqueued-sender-com-spec{data-element=FlgVal, init-value=0}, provided-interface=OBDSperrungKaltstartDenom
      ObdKaltstartDenominator: nonqueued-sender-com-spec{data-element=FlgVal, init-value=0}, provided-interface=ObdKaltstartDenominator
    4 x require port:
      TempPerformanceIndcrDcDc: required-interface=TempPerformanceIndcrDcDc
        required-com-specs:
          data-element=TempIndcrVal, filter=data-filter-type=ALWAYS, init-value=0 Percent
          data-element=TempIndcrValSts, filter=data-filter-type=ALWAYS, init-value=fields=[0 Percent, 0 Percent]
      Em1OffsLrng: required-interface=Em1OffsLrng
        required-com-specs:
          data-element=Req, filter=data-filter-type=ALWAYS, init-value=0
          data-element=Cmpl, filter=data-filter-type=ALWAYS, init-value=0
      Em2OffsLrng: required-interface=Em2OffsLrng
        required-com-specs:
          data-element=Req, filter=data-filter-type=ALWAYS, init-value=0
          data-element=Cmpl, filter=data-filter-type=ALWAYS, init-value=0
      RP_IF_MO_Eta_Verschlechterung_XIX_Grundumfang_XIX_LE_TWIN: nonqueued-receiver-com-spec{data-element=DE_MO_Eta_Verschlechterung, enable-update=true, filter=data-filter-type=ALWAYS, init-value=0}, required-interface=IF_MO_Eta_Verschlechterung
    provide port IceSpdAct: nonqueued-sender-com-spec{data-element=SpdVal, init-value=0 rpm}, provided-interface=IceSpdAct
    provide port EngCoolantT: nonqueued-sender-com-spec{data-element=ValSts, init-value=fields=[New:0, Status:0]}, provided-interface=EngCoolantT
    require port RP_IF_OBD_Eng_Cool_Temp_XIX_Grundumfang_XIX_LE_TWIN_DE_OBD_Eng_Cool_Temp: nonqueued-receiver-com-spec{data-element=DE_OBD_Eng_Cool_Temp, filter=data-filter-type=ALWAYS}, required-interface=IF_OBD_Eng_Cool_Temp
    provide port SP_IF_LE1_MI_related_Error_Status: nonqueued-sender-com-spec{data-element=DE_LE1_MI_related_Error_Status, init-value=0}, provided-interface=IF_LE1_MI_related_Error_Status
    require port MIError: nonqueued-receiver-com-spec{data-element=Sts, filter=data-filter-type=ALWAYS, init-value=0}, required-interface=MIError
    provide port NetIoMgr250msEvents: nonqueued-sender-com-spec{data-element=Status, init-value=[255, 255]}, provided-interface=NetIoMgr250msEvents
    7 x require port:
      PeWtrCooltInletTEstimd: nonqueued-receiver-com-spec{data-element=ValSts, filter=data-filter-type=ALWAYS, init-value=fields=[20 degC, 0 degC]}, required-interface=PeWtrCooltInletTEstimd
      DiagnosticInfo_Motor57: required-interface=DiagnosticInfo_Motor57
        required-com-specs:
          GetMonitorStatus
          GetFaultDetectionCounter
          GetEventUdsStatus
          GetEventTested
          GetEventStatus
          GetEventFreezeFrameDataEx
          GetEventFreezeFrameData
          GetEventFailed
          GetEventExtendedDataRecordEx
          GetEventExtendedDataRecord
          GetEventAvailable
          GetDTCOfEvent
          GetDebouncingOfEvent
      DiagnosticInfo_CluEng_01: required-interface=DiagnosticInfo
        required-com-specs:
          GetMonitorStatus
          GetFaultDetectionCounter
          GetEventUdsStatus
          GetEventTested
          GetEventStatus
          GetEventFreezeFrameDataEx
          GetEventFreezeFrameData
          GetEventFailed
          GetEventExtendedDataRecordEx
          GetEventExtendedDataRecord
          GetEventAvailable
          GetDTCOfEvent
          GetDebouncingOfEvent
      DiagnosticInfo_Motor_07: required-interface=DiagnosticInfo
        required-com-specs:
          GetMonitorStatus
          GetFaultDetectionCounter
          GetEventUdsStatus
          GetEventTested
          GetEventStatus
          GetEventFreezeFrameDataEx
          GetEventFreezeFrameData
          GetEventFailed
          GetEventExtendedDataRecordEx
          GetEventExtendedDataRecord
          GetEventAvailable
          GetDTCOfEvent
          GetDebouncingOfEvent
      DiagnosticInfo_Motor_31: required-interface=DiagnosticInfo
        required-com-specs:
          GetMonitorStatus
          GetFaultDetectionCounter
          GetEventUdsStatus
          GetEventTested
          GetEventStatus
          GetEventFreezeFrameDataEx
          GetEventFreezeFrameData
          GetEventFailed
          GetEventExtendedDataRecordEx
          GetEventExtendedDataRecord
          GetEventAvailable
          GetDTCOfEvent
          GetDebouncingOfEvent
      DiagnosticInfo_Motor_54: required-interface=DiagnosticInfo
        required-com-specs:
          GetMonitorStatus
          GetFaultDetectionCounter
          GetEventUdsStatus
          GetEventTested
          GetEventStatus
          GetEventFreezeFrameDataEx
          GetEventFreezeFrameData
          GetEventFailed
          GetEventExtendedDataRecordEx
          GetEventExtendedDataRecord
          GetEventAvailable
          GetDTCOfEvent
          GetDebouncingOfEvent
      DiagnosticInfo_Etm_01: required-interface=DiagnosticInfo
        required-com-specs:
          GetMonitorStatus
          GetFaultDetectionCounter
          GetEventUdsStatus
          GetEventTested
          GetEventStatus
          GetEventFreezeFrameDataEx
          GetEventFreezeFrameData
          GetEventFailed
          GetEventExtendedDataRecordEx
          GetEventExtendedDataRecord
          GetEventAvailable
          GetDTCOfEvent
          GetDebouncingOfEvent
    provide port EngCooltTQBit: nonqueued-sender-com-spec{data-element=ValSts, init-value=fields=[New:0, Status:0]}, provided-interface=EngCooltTQBit
    provide port WtrCooltStatus: nonqueued-sender-com-spec{data-element=ValSts, init-value=fields=[New:0, Status:0]}, provided-interface=WtrCooltStatus
    provide port ObdMinimumTrip: nonqueued-sender-com-spec{data-element=FlgVal, init-value=0}, provided-interface=ObdMinimumTrip
    require port RP_IF_OBD_Minimum_Trip_XIX_Grundumfang_XIX_LE_TWIN: nonqueued-receiver-com-spec{data-element=DE_OBD_Minimum_Trip, filter=data-filter-type=ALWAYS, init-value=0}, required-interface=IF_OBD_Minimum_Trip
    provide port VehVActState: nonqueued-sender-com-spec{data-element=bool, init-value=0}, provided-interface=VehVActState
    behavior NetIoMgr_InternalBehavior: data-type-mapping=[DataTypeMappingSet_0, DataTypeMappingSet_0, NmUsrDt_SwcKL15_DataTypeMappingSet, DataTypeMappingSets, ApplMappingSet]
      timing event TMT_Main1ms_NetworkIoHandler: start-on-event=Main1ms_NetworkIoHandler, period=0.001
      timing event TMT_NetIoMgr_Main: start-on-event=NetIoMgr_MainFunction, period=0.01
      port-api-options:
        enable-take-address=false, error-handling=TRANSFORMER-ERROR-HANDLING, indirect-api=false, port=RP_IF_SG_Airbag_01
        enable-take-address=false, error-handling=TRANSFORMER-ERROR-HANDLING, indirect-api=false, port=RP_IF_SG_ESP_21
        enable-take-address=false, error-handling=TRANSFORMER-ERROR-HANDLING, indirect-api=false, port=RP_IF_SG_HVK_01
        enable-take-address=false, error-handling=TRANSFORMER-ERROR-HANDLING, indirect-api=false, port=RP_IF_SG_Klemmen_Status_01
        enable-take-address=false, error-handling=TRANSFORMER-ERROR-HANDLING, indirect-api=false, port=RP_IF_SG_Motor_56
      runnable CSDataServices_MonBComCanMsg0X6B2RxTimeTimeout_DiagnosticInfo
        sync call SC_Diagnose_TimeoutSts_GetEventStatus: operation=Diagnose_TimeoutSts.GetEventStatus
      runnable Main1ms_NetworkIoHandler
        data-receive-point-by-arguments:
          33 x access:
            REC_DcDcCnvrPwrLossEstimd_PwrValQf: accessed-variable=DcDcCnvrPwrLossEstimd.PwrValQf
            REC_Em1AirgapTqLimMax_TqMaxValSts: accessed-variable=Em1AirgapTqLimMax.TqMaxValSts
            REC_NDCPe1CtrlCddCurr_IdcValSts: accessed-variable=NDCPe1CtrlCddCurr.IdcValSts
            REC_NDCPe2CtrlCddCurr_IdcValSts: accessed-variable=NDCPe2CtrlCddCurr.IdcValSts
            REC_DcLnkVoltFild_DcLnkVSts: accessed-variable=DcLnkVoltFild.DcLnkVSts
            REC_Em1AirgapTqLimMax_TqMaxVal: accessed-variable=Em1AirgapTqLimMax.TqMaxVal
            REC_Em1AirgapTqLimMin_TqMinValSts: accessed-variable=Em1AirgapTqLimMin.TqMinValSts
            REC_Em1AirgapTqMax_TqMaxValSts: accessed-variable=Em1AirgapTqMax.TqMaxValSts
            REC_Em1AirgapTqMaxTot_TqMaxValSts: accessed-variable=Em1AirgapTqMaxTot.TqMaxValSts
            REC_Em1AirgapTqMin_TqMinValSts: accessed-variable=Em1AirgapTqMin.TqMinValSts
            REC_Em1AirgapTqMinTot_TqMinValSts: accessed-variable=Em1AirgapTqMinTot.TqMinValSts
            REC_Em1AirgapTqOver_FlgVal: accessed-variable=Em1AirgapTqOver.FlgVal
            REC_Em1AscErrorReaction_StsVal: accessed-variable=Em1AscErrorReaction.StsVal
            REC_Em1BattShutDwn_StsVal: accessed-variable=Em1BattShutDwn.StsVal
            REC_Em1SpdActFild_SpdValSts: accessed-variable=Em1SpdActFild.SpdValSts
            REC_NDCPe1CtrlCddCurr_IdcVal: accessed-variable=NDCPe1CtrlCddCurr.IdcVal
            REC_Em2AirgapTqLimMax_TqMaxValSts: accessed-variable=Em2AirgapTqLimMax.TqMaxValSts
            REC_Em2AirgapTqLimMin_TqMinValSts: accessed-variable=Em2AirgapTqLimMin.TqMinValSts
            REC_Em2AirgapTqMax_TqMaxValSts: accessed-variable=Em2AirgapTqMax.TqMaxValSts
            REC_Em2AirgapTqMaxTot_TqMaxValSts: accessed-variable=Em2AirgapTqMaxTot.TqMaxValSts
            REC_Em2AirgapTqMin_TqMinValSts: accessed-variable=Em2AirgapTqMin.TqMinValSts
            REC_Em2AirgapTqMinTot_TqMinValSts: accessed-variable=Em2AirgapTqMinTot.TqMinValSts
            REC_Em2AirgapTqOver_FlgVal: accessed-variable=Em2AirgapTqOver.FlgVal
            REC_Em2AscErrorReaction_StsVal: accessed-variable=Em2AscErrorReaction.StsVal
            REC_Em2BattShutDwn_StsVal: accessed-variable=Em2BattShutDwn.StsVal
            REC_Em2SpdActFild_SpdValSts: accessed-variable=Em2SpdActFild.SpdValSts
            REC_NDCPe2CtrlCddCurr_IdcVal: accessed-variable=NDCPe2CtrlCddCurr.IdcVal
            REC_PECOutIf_bDampCtl_VW_PECOutIf_bDampCtl_VW: accessed-variable=PECOutIf_bDampCtl_VW.PECOutIf_bDampCtl_VW
            REC_PECOutIf_nWhlAbsLe_VW_PECOutIf_nWhlAbsLe_VW: accessed-variable=PECOutIf_nWhlAbsLe_VW.PECOutIf_nWhlAbsLe_VW
            REC_PECOutIf_nWhlAbsRi_VW_PECOutIf_nWhlAbsRi_VW: accessed-variable=PECOutIf_nWhlAbsRi_VW.PECOutIf_nWhlAbsRi_VW
            REC_PECOutIf_stSpdlCtl_VW_PECOutIf_stSpdlCtl_VW: accessed-variable=PECOutIf_stSpdlCtl_VW.PECOutIf_stSpdlCtl_VW
            REC_PECOutIf_tqDamp_VW_PECOutIf_tqDamp_VW: accessed-variable=PECOutIf_tqDamp_VW.PECOutIf_tqDamp_VW
            REC_PECOutIf_tqSpSpdl_VW_PECOutIf_tqSpSpdl_VW: accessed-variable=PECOutIf_tqSpSpdl_VW.PECOutIf_tqSpSpdl_VW
        data-send-points:
          32 x access:
            SEND_CanMsg_EM1_01_Qm_DT_SG_EM1_01: accessed-variable=CanMsg_EM1_01_Qm.DT_SG_EM1_01
            SEND_CanMsg_EM2_01_Qm_DT_SG_EM2_01: accessed-variable=CanMsg_EM2_01_Qm.DT_SG_EM2_01
            SEND_DcConnectorILim_MaxIValSts: accessed-variable=DcConnectorILim.MaxIValSts
            SEND_DcConnectorILim_MinIValSts: accessed-variable=DcConnectorILim.MinIValSts
            SEND_Eds1CtrlModTar_ModVal: accessed-variable=Eds1CtrlModTar.ModVal
            SEND_Eds1MaxPwr_PwrValSts: accessed-variable=Eds1MaxPwr.PwrValSts
            SEND_Eds1MinPwr_PwrValSts: accessed-variable=Eds1MinPwr.PwrValSts
            SEND_Eds2CtrlModTar_ModVal: accessed-variable=Eds2CtrlModTar.ModVal
            SEND_Eds2MaxPwr_PwrValSts: accessed-variable=Eds2MaxPwr.PwrValSts
            SEND_Eds2MinPwr_PwrValSts: accessed-variable=Eds2MinPwr.PwrValSts
            SEND_Em1AirgapTqAllwdMax_TqMaxValSts: accessed-variable=Em1AirgapTqAllwdMax.TqMaxValSts
            SEND_Em1AirgapTqAllwdMin_TqMinValSts: accessed-variable=Em1AirgapTqAllwdMin.TqMinValSts
            SEND_Em1AirgapTqTar_TqValSts: accessed-variable=Em1AirgapTqTar.TqValSts
            SEND_Em1CurrMaxLim_IMaxValSts: accessed-variable=Em1CurrMaxLim.IMaxValSts
            SEND_Em1CurrMinLim_IMinValSts: accessed-variable=Em1CurrMinLim.IMinValSts
            SEND_Em2AirgapTqAllwdMax_TqMaxValSts: accessed-variable=Em2AirgapTqAllwdMax.TqMaxValSts
            SEND_Em2AirgapTqAllwdMin_TqMinValSts: accessed-variable=Em2AirgapTqAllwdMin.TqMinValSts
            SEND_Em2AirgapTqTar_TqVal: accessed-variable=Em2AirgapTqTar.TqVal
            SEND_Em2AirgapTqTar_TqValSts: accessed-variable=Em2AirgapTqTar.TqValSts
            SEND_Em2CurrMaxLim_IMaxValSts: accessed-variable=Em2CurrMaxLim.IMaxValSts
            SEND_Em2CurrMinLim_IMinValSts: accessed-variable=Em2CurrMinLim.IMinValSts
            SEND_PECInIf_facDamp_VW_PECInIf_facDamp_VW: accessed-variable=PECInIf_facDamp_VW.PECInIf_facDamp_VW
            SEND_PECInIf_nMax_VW_PECInIf_nMax_VW: accessed-variable=PECInIf_nMax_VW.PECInIf_nMax_VW
            SEND_PECInIf_nMin_VW_PECInIf_nMin_VW: accessed-variable=PECInIf_nMin_VW.PECInIf_nMin_VW
            SEND_PECInIf_stReqDampCtl_VW_PECInIf_stReqDampCtl_VW: accessed-variable=PECInIf_stReqDampCtl_VW.PECInIf_stReqDampCtl_VW
            SEND_PECInIf_tqDampThd_VW_PECInIf_tqDampThd_VW: accessed-variable=PECInIf_tqDampThd_VW.PECInIf_tqDampThd_VW
            SEND_PECInIf_tqSp_VW_PECInIf_tqSp_VW: accessed-variable=PECInIf_tqSp_VW.PECInIf_tqSp_VW
            SEND_PECInIf_vWhlFrntLe_VW_PECInIf_vWhlFrntLe_VW: accessed-variable=PECInIf_vWhlFrntLe_VW.PECInIf_vWhlFrntLe_VW
            SEND_PECInIf_vWhlFrntRi_VW_PECInIf_vWhlFrntRi_VW: accessed-variable=PECInIf_vWhlFrntRi_VW.PECInIf_vWhlFrntRi_VW
            SEND_VehVAct_ValSts: accessed-variable=VehVAct.ValSts
            SEND_VehVAct_VVal: accessed-variable=VehVAct.VVal
            SEND_VehVActState_bool: accessed-variable=VehVActState.bool
        sync call SC_Vtg_EnableCondition_SetEnableCondition: operation=Vtg_EnableCondition.SetEnableCondition
      runnable NetIoMgr_MainFunction: mode-access-points=[KL30_OverVoltage.VoltageMonitorMode, KL30_UnderVoltage.VoltageMonitorMode, currentKL15ModePort.KL]
        data-receive-point-by-arguments:
          191 x access:
            REC_ActiveReactions_Status: accessed-variable=ActiveReactions.Status
            REC_ActiveReactionsExtended_Status: accessed-variable=ActiveReactionsExtended.Status
            REC_Clamp15_ValSts: accessed-variable=Clamp15.ValSts
            REC_DcConnectorPwr_ValSts: accessed-variable=DcConnectorPwr.ValSts
            REC_DcDcCnvrPwrLossEstimd_PwrVal: accessed-variable=DcDcCnvrPwrLossEstimd.PwrVal
            REC_DcDcCnvrPwrMax_ValSts: accessed-variable=DcDcCnvrPwrMax.ValSts
            REC_DcDcCnvrPwrMin_ValSts: accessed-variable=DcDcCnvrPwrMin.ValSts
            REC_DhtWtrCooltT_TTarValSts: accessed-variable=DhtWtrCooltT.TTarValSts
            REC_DhtWtrCooltVolFlow_VolTarValSts: accessed-variable=DhtWtrCooltVolFlow.VolTarValSts
            REC_Eds1PwrPerformanceIndcr_PwrIndcrValSts: accessed-variable=Eds1PwrPerformanceIndcr.PwrIndcrValSts
            REC_Eds1TempPerformanceIndcr_TempIndcrValSts: accessed-variable=Eds1TempPerformanceIndcr.TempIndcrValSts
            REC_Eds1TqPerformanceIndcr_TqIndcrValSts: accessed-variable=Eds1TqPerformanceIndcr.TqIndcrValSts
            REC_Eds2PwrPerformanceIndcr_PwrIndcrValSts: accessed-variable=Eds2PwrPerformanceIndcr.PwrIndcrValSts
            REC_Eds2TempPerformanceIndcr_TempIndcrValSts: accessed-variable=Eds2TempPerformanceIndcr.TempIndcrValSts
            REC_Eds2TqPerformanceIndcr_TqIndcrValSts: accessed-variable=Eds2TqPerformanceIndcr.TqIndcrValSts
            REC_Em1ActvDchaSrcErr_ErrSts: accessed-variable=Em1ActvDchaSrcErr.ErrSts
            REC_Em1ActvDchaSrcErr_StsVal: accessed-variable=Em1ActvDchaSrcErr.StsVal
            REC_Em1AirgapPwrChartcMax_PwrMaxValSts: accessed-variable=Em1AirgapPwrChartcMax.PwrMaxValSts
            REC_Em1AirgapPwrCpbyHi_PwrValSts: accessed-variable=Em1AirgapPwrCpbyHi.PwrValSts
            REC_Em1AirgapPwrCpbyLo_PwrValSts: accessed-variable=Em1AirgapPwrCpbyLo.PwrValSts
            REC_Em1AirgapTqAddlGenr_TqQf: accessed-variable=Em1AirgapTqAddlGenr.TqQf
            REC_Em1AirgapTqAddlGenr_TqVal: accessed-variable=Em1AirgapTqAddlGenr.TqVal
            REC_Em1AirgapTqChartcMax_TqMaxValSts: accessed-variable=Em1AirgapTqChartcMax.TqMaxValSts
            REC_Em1AirgapTqCpbyHi_TqValSts: accessed-variable=Em1AirgapTqCpbyHi.TqValSts
            REC_Em1AirgapTqCpbyLo_TqValSts: accessed-variable=Em1AirgapTqCpbyLo.TqValSts
            REC_EM1DetnFreeVolt_StsVal: accessed-variable=EM1DetnFreeVolt.StsVal
            REC_EM1DetnOpenHVWire_StsVal: accessed-variable=EM1DetnOpenHVWire.StsVal
            REC_Em1FwErrorReaction_StsVal: accessed-variable=Em1FwErrorReaction.StsVal
            REC_Em1ParkenWfs_Sts: accessed-variable=Em1ParkenWfs.Sts
            REC_Em1RtmWarnOverCurrent_Val: accessed-variable=Em1RtmWarnOverCurrent.Val
            REC_Em1RtmWarnOverSpeed_Val: accessed-variable=Em1RtmWarnOverSpeed.Val
            REC_Em1RtmWarnTmpEm_Val: accessed-variable=Em1RtmWarnTempEm.Val
            REC_Em1RtmWarnTmpPwr_Val: accessed-variable=Em1RtmWarnTempPwr.Val
            REC_Em1SpdActvScLoInit_SpdValSts: accessed-variable=Em1SpdActvScLoInit.SpdValSts
            REC_Em1StatorWindgTEstimd_TValSts: accessed-variable=Em1StatorWindgTEstimd.TValSts
            REC_Em2ActvDchaSrcErr_ErrSts: accessed-variable=Em2ActvDchaSrcErr.ErrSts
            REC_Em2ActvDchaSrcErr_StsVal: accessed-variable=Em2ActvDchaSrcErr.StsVal
            REC_Em2AirgapPwrChartcMax_PwrMaxValSts: accessed-variable=Em2AirgapPwrChartcMax.PwrMaxValSts
            REC_Em2AirgapPwrCpbyHi_PwrValSts: accessed-variable=Em2AirgapPwrCpbyHi.PwrValSts
            REC_Em2AirgapPwrCpbyLo_PwrValSts: accessed-variable=Em2AirgapPwrCpbyLo.PwrValSts
            REC_Em2AirgapTqAddlGenr_TqValSts: accessed-variable=Em2AirgapTqAddlGenr.TqValSts
            REC_Em2AirgapTqChartcMax_TqMaxValSts: accessed-variable=Em2AirgapTqChartcMax.TqMaxValSts
            REC_Em2AirgapTqCpbyHi_TqValSts: accessed-variable=Em2AirgapTqCpbyHi.TqValSts
            REC_Em2AirgapTqCpbyLo_TqValSts: accessed-variable=Em2AirgapTqCpbyLo.TqValSts
            REC_EM2DetnFreeVolt_StsVal: accessed-variable=EM2DetnFreeVolt.StsVal
            REC_EM2DetnOpenHVWire_StsVal: accessed-variable=EM2DetnOpenHVWire.StsVal
            REC_Em2FwErrorReaction_StsVal: accessed-variable=Em2FwErrorReaction.StsVal
            REC_Em2RtmWarnOverCurrent_Val: accessed-variable=Em2RtmWarnOverCurrent.Val
            REC_Em2RtmWarnOverSpeed_Val: accessed-variable=Em2RtmWarnOverSpeed.Val
            REC_Em2RtmWarnTmpEm_Val: accessed-variable=Em2RtmWarnTempEm.Val
            REC_Em2RtmWarnTmpPwr_Val: accessed-variable=Em2RtmWarnTempPwr.Val
            REC_Em2SpdAct_SpdQf: accessed-variable=Em2SpdAct.SpdQf
            REC_Em2SpdAct_SpdVal: accessed-variable=Em2SpdAct.SpdVal
            REC_Em2SpdActvScLoInit_SpdValSts: accessed-variable=Em2SpdActvScLoInit.SpdValSts
            REC_Em2StatorWindgTEstimd_TValSts: accessed-variable=Em2StatorWindgTEstimd.TValSts
            REC_IF_MO_Drehzahl_VM_DE_MO_Drehzahl_VM: accessed-variable=RP_IF_MO_Drehzahl_VM_DE_MO_Drehzahl_VM.DE_MO_Drehzahl_VM
            REC_IF_MO_Kuehlmittel_Temp_DE_MO_Kuehlmittel_Temp: accessed-variable=RP_IF_MO_Kuehlmittel_Temp.DE_MO_Kuehlmittel_Temp
            REC_IF_MO_QBit_Kuehlmittel_Temp_DE_MO_QBit_Kuehlmittel_Temp: accessed-variable=RP_IF_MO_QBit_Kuehlmittel_Temp.DE_MO_QBit_Kuehlmittel_Temp
            REC_IF_OBD_Aussen_Temp_gef_DE_OBD_Aussen_Temp_gef: accessed-variable=RP_IF_OBD_Aussen_Temp_gef.DE_OBD_Aussen_Temp_gef
            REC_HeatExWtrCooltOutlT_TValSts: accessed-variable=HeatExWtrCooltOutlT.TValSts
            REC_DcDcCnvrPwrLossEstimd_PwrValSts: accessed-variable=DcDcCnvrPwrLossEstimd.PwrValSts
            REC_InsMonError_StsVal: accessed-variable=InsMonError.StsVal
            REC_InsMonState_ErrSts: accessed-variable=InsMonState.ErrSts
            REC_InsMonState_Sts: accessed-variable=InsMonState.Sts
            REC_OBDLampReq_Sts: accessed-variable=OBDLampReq.Sts
            REC_Pe1Energies_Val: accessed-variable=Pe1Energies.Val
            REC_Pe2Energies_Val: accessed-variable=Pe2Energies.Val
            REC_PECOutIf_bDampCtl_VW_PECOutIf_bDampCtl_VW: accessed-variable=PECOutIf_bDampCtl_VW.PECOutIf_bDampCtl_VW
            REC_PECOutIf_nWhlAbsLe_VW_PECOutIf_nWhlAbsLe_VW: accessed-variable=PECOutIf_nWhlAbsLe_VW.PECOutIf_nWhlAbsLe_VW
            REC_PECOutIf_nWhlAbsRi_VW_PECOutIf_nWhlAbsRi_VW: accessed-variable=PECOutIf_nWhlAbsRi_VW.PECOutIf_nWhlAbsRi_VW
            REC_PECOutIf_stSpdlCtl_VW_PECOutIf_stSpdlCtl_VW: accessed-variable=PECOutIf_stSpdlCtl_VW.PECOutIf_stSpdlCtl_VW
            REC_PECOutIf_tqDamp_VW_PECOutIf_tqDamp_VW: accessed-variable=PECOutIf_tqDamp_VW.PECOutIf_tqDamp_VW
            REC_PECOutIf_tqSpSpdl_VW_PECOutIf_tqSpSpdl_VW: accessed-variable=PECOutIf_tqSpSpdl_VW.PECOutIf_tqSpSpdl_VW
            REC_RP_Em1BlockingInfoWfs_StsVal: accessed-variable=RP_Em1BlockingInfoWfs.StsVal
            REC_RP_Em1ReleaseExpInfoWfs_StsVal: accessed-variable=RP_Em1ReleaseExpInfoWfs.StsVal
            REC_RP_Em1ReleaseInfoWfs_StsVal: accessed-variable=RP_Em1ReleaseInfoWfs.StsVal
            REC_RP_IF_BR_QBit_Reifenumfang_XIX_Grundumfang_XIX_LE_TWIN_DE_BR_QBit_Reifenumfang: accessed-variable=RP_IF_BR_QBit_Reifenumfang_XIX_Grundumfang_XIX_LE_TWIN.DE_BR_QBit_Reifenumfang
            REC_RP_IF_BR_Reifenumfang_XIX_Grundumfang_XIX_LE_TWIN_DE_BR_Reifenumfang: accessed-variable=RP_IF_BR_Reifenumfang_XIX_Grundumfang_XIX_LE_TWIN.DE_BR_Reifenumfang
            REC_RP_IF_CluEng_Avl_XIX_Grundumfang_XIX_LE_TWIN_DE_CluEng_Avl: accessed-variable=RP_IF_CluEng_Avl_XIX_Grundumfang_XIX_LE_TWIN.DE_CluEng_Avl
            REC_RP_IF_CluEng_State_XIX_Grundumfang_XIX_LE_TWIN_DE_CluEng_State: accessed-variable=RP_IF_CluEng_State_XIX_Grundumfang_XIX_LE_TWIN.DE_CluEng_State
            REC_RP_IF_ESP_VL_Radgeschw_02_XIX_Grundumfang_XIX_LE_TWIN_DE_ESP_VL_Radgeschw_02: accessed-variable=RP_IF_ESP_VL_Radgeschw_02_XIX_Grundumfang_XIX_LE_TWIN.DE_ESP_VL_Radgeschw_02
            REC_RP_IF_ESP_VR_Radgeschw_02_XIX_Grundumfang_XIX_LE_TWIN_DE_ESP_VR_Radgeschw_02: accessed-variable=RP_IF_ESP_VR_Radgeschw_02_XIX_Grundumfang_XIX_LE_TWIN.DE_ESP_VR_Radgeschw_02
            REC_RP_IF_ESP_Zaehnezahl_XIX_Grundumfang_XIX_LE_TWIN_DE_ESP_Zaehnezahl: accessed-variable=RP_IF_ESP_Zaehnezahl_XIX_Grundumfang_XIX_LE_TWIN.DE_ESP_Zaehnezahl
            REC_RP_IF_eTM_Pumpe1_Status_XIX_Grundumfang_XIX_LE_TWIN_DE_eTM_Pumpe1_Status: accessed-variable=RP_IF_eTM_Pumpe1_Status_XIX_Grundumfang_XIX_LE_TWIN.DE_eTM_Pumpe1_Status
            REC_RP_IF_eTM_Pumpe1_Volumenstrom_XIX_Grundumfang_XIX_LE_TWIN_DE_eTM_Pumpe1_Volumenstrom: accessed-variable=RP_IF_eTM_Pumpe1_Volumenstrom_XIX_Grundumfang_XIX_LE_TWIN.DE_eTM_Pumpe1_Volumenstrom
            REC_RP_IF_eTM_Pumpe1_Volumenstromteilung_XIX_Grundumfang_XIX_LE_TWIN_DE_eTM_Pumpe1_Volumenstromteilung: accessed-variable=RP_IF_eTM_Pumpe1_Volumenstromteilung_XIX_Grundumfang_XIX_LE_TWIN.DE_eTM_Pumpe1_Volumenstromteilung
            REC_RP_IF_eTM_Pumpe2_Status_XIX_Grundumfang_XIX_LE_TWIN_DE_eTM_Pumpe2_Status: accessed-variable=RP_IF_eTM_Pumpe2_Status_XIX_Grundumfang_XIX_LE_TWIN.DE_eTM_Pumpe2_Status
            REC_RP_IF_eTM_Pumpe2_Volumenstrom_XIX_Grundumfang_XIX_LE_TWIN_DE_eTM_Pumpe2_Volumenstrom: accessed-variable=RP_IF_eTM_Pumpe2_Volumenstrom_XIX_Grundumfang_XIX_LE_TWIN.DE_eTM_Pumpe2_Volumenstrom
            REC_RP_IF_eTM_Pumpe3_Status_XIX_Grundumfang_XIX_LE_TWIN_DE_eTM_Pumpe3_Status: accessed-variable=RP_IF_eTM_Pumpe3_Status_XIX_Grundumfang_XIX_LE_TWIN.DE_eTM_Pumpe3_Status
            REC_RP_IF_eTM_Temperatur_1_XIX_Grundumfang_XIX_LE_TWIN_DE_eTM_Temperatur_1: accessed-variable=RP_IF_eTM_Temperatur_1_XIX_Grundumfang_XIX_LE_TWIN.DE_eTM_Temperatur_1
            REC_RP_IF_eTM_Temperatur_2_XIX_Grundumfang_XIX_LE_TWIN_DE_eTM_Temperatur_2: accessed-variable=RP_IF_eTM_Temperatur_2_XIX_Grundumfang_XIX_LE_TWIN.DE_eTM_Temperatur_2
            REC_RP_IF_ImoCord_Auth_Aufforderung_WFS_XIX_Grundumfang_XIX_LE_TWIN_DE_ImoCord_Auth_Aufforderung_WFS: accessed-variable=RP_IF_ImoCord_Auth_Aufforderung_WFS_XIX_Grundumfang_XIX_LE_TWIN.DE_ImoCord_Auth_Aufforderung_WFS
            REC_RP_IF_KBI_Kilometerstand_XIX_Grundumfang_XIX_LE_TWIN_DE_KBI_Kilometerstand: accessed-variable=RP_IF_KBI_Kilometerstand_XIX_Grundumfang_XIX_LE_TWIN.DE_KBI_Kilometerstand
            REC_RP_IF_KST_Sonderzustand_Status_XIX_Grundumfang_XIX_LE_TWIN_DE_KST_Sonderzustand_Status: accessed-variable=RP_IF_KST_Sonderzustand_Status_XIX_Grundumfang_XIX_LE_TWIN.DE_KST_Sonderzustand_Status
            REC_RP_IF_KST_WFS_Fahrfreigabe_Anforderung_XIX_Grundumfang_XIX_LE_TWIN_DE_KST_WFS_Fahrfreigabe_Anforderung: accessed-variable=RP_IF_KST_WFS_Fahrfreigabe_Anforderung_XIX_Grundumfang_XIX_LE_TWIN.DE_KST_WFS_Fahrfreigabe_Anforderung
            REC_RP_IF_LCU_IstOelVolumenstrom_XIX_Grundumfang_XIX_LE_TWIN_DE_LCU_IstOelVolumenstrom: accessed-variable=RP_IF_LCU_IstOelVolumenstrom_XIX_Grundumfang_XIX_LE_TWIN.DE_LCU_IstOelVolumenstrom
            REC_RP_IF_LCU_OelTempPlausi_XIX_Grundumfang_XIX_LE_TWIN_DE_LCU_OelTempPlausi: accessed-variable=RP_IF_LCU_OelTempPlausi_XIX_Grundumfang_XIX_LE_TWIN.DE_LCU_OelTempPlausi
            REC_RP_IF_MO_Drehzahl_01_XIX_Grundumfang_XIX_LE_TWIN_DE_MO_Drehzahl_01: accessed-variable=RP_IF_MO_Drehzahl_01_XIX_Grundumfang_XIX_LE_TWIN.DE_MO_Drehzahl_01
            REC_RP_IF_MO_EM1_Generator_Leistung_XIX_Grundumfang_XIX_LE_TWIN_DE_MO_EM1_Generator_Leistung: accessed-variable=RP_IF_MO_EM1_Generator_Leistung_XIX_Grundumfang_XIX_LE_TWIN.DE_MO_EM1_Generator_Leistung
            REC_RP_IF_MO_EM1_Max_Leistung_Gesamt_XIX_Grundumfang_XIX_LE_TWIN_DE_MO_EM1_Max_Leistung_Gesamt: accessed-variable=RP_IF_MO_EM1_Max_Leistung_Gesamt_XIX_Grundumfang_XIX_LE_TWIN.DE_MO_EM1_Max_Leistung_Gesamt
            REC_RP_IF_MO_EM1_Max_Spannung_Lim_XIX_Grundumfang_XIX_LE_TWIN_DE_MO_EM1_Max_Spannung_Lim: accessed-variable=RP_IF_MO_EM1_Max_Spannung_Lim_XIX_Grundumfang_XIX_LE_TWIN.DE_MO_EM1_Max_Spannung_Lim
            REC_RP_IF_MO_EM1_Min_Leistung_Gesamt_XIX_Grundumfang_XIX_LE_TWIN_DE_MO_EM1_Min_Leistung_Gesamt: accessed-variable=RP_IF_MO_EM1_Min_Leistung_Gesamt_XIX_Grundumfang_XIX_LE_TWIN.DE_MO_EM1_Min_Leistung_Gesamt
            REC_RP_IF_MO_EM1_Min_Spannung_Lim_XIX_Grundumfang_XIX_LE_TWIN_DE_MO_EM1_Min_Spannung_Lim: accessed-variable=RP_IF_MO_EM1_Min_Spannung_Lim_XIX_Grundumfang_XIX_LE_TWIN.DE_MO_EM1_Min_Spannung_Lim
            REC_RP_IF_MO_EM2_Generator_Leistung_XIX_Grundumfang_XIX_LE_TWIN_DE_MO_EM2_Generator_Leistung: accessed-variable=RP_IF_MO_EM2_Generator_Leistung_XIX_Grundumfang_XIX_LE_TWIN.DE_MO_EM2_Generator_Leistung
            REC_RP_IF_MO_EM2_Max_Leistung_Gesamt_XIX_Grundumfang_XIX_LE_TWIN_DE_MO_EM2_Max_Leistung_Gesamt: accessed-variable=RP_IF_MO_EM2_Max_Leistung_Gesamt_XIX_Grundumfang_XIX_LE_TWIN.DE_MO_EM2_Max_Leistung_Gesamt
            REC_RP_IF_MO_EM2_Max_Spannung_Lim_XIX_Grundumfang_XIX_LE_TWIN_DE_MO_EM2_Max_Spannung_Lim: accessed-variable=RP_IF_MO_EM2_Max_Spannung_Lim_XIX_Grundumfang_XIX_LE_TWIN.DE_MO_EM2_Max_Spannung_Lim
            REC_RP_IF_MO_EM2_Min_Leistung_Gesamt_XIX_Grundumfang_XIX_LE_TWIN_DE_MO_EM2_Min_Leistung_Gesamt: accessed-variable=RP_IF_MO_EM2_Min_Leistung_Gesamt_XIX_Grundumfang_XIX_LE_TWIN.DE_MO_EM2_Min_Leistung_Gesamt
            REC_RP_IF_MO_EM2_Min_Spannung_Lim_XIX_Grundumfang_XIX_LE_TWIN_DE_MO_EM2_Min_Spannung_Lim: accessed-variable=RP_IF_MO_EM2_Min_Spannung_Lim_XIX_Grundumfang_XIX_LE_TWIN.DE_MO_EM2_Min_Spannung_Lim
            REC_RP_IF_MO_ErwGrenzen_Anf_XIX_Grundumfang_XIX_LE_TWIN_DE_MO_ErwGrenzen_Anf: accessed-variable=RP_IF_MO_ErwGrenzen_Anf_XIX_Grundumfang_XIX_LE_TWIN.DE_MO_ErwGrenzen_Anf
            REC_RP_IF_MO_Fahrbereitschaft_XIX_Grundumfang_XIX_LE_TWIN_DE_MO_Fahrbereitschaft: accessed-variable=RP_IF_MO_Fahrbereitschaft_XIX_Grundumfang_XIX_LE_TWIN.DE_MO_Fahrbereitschaft
            REC_RP_IF_MO_Fahrzeugabstellzeit_Status_XIX_Grundumfang_XIX_LE_TWIN_DE_MO_Fahrzeugabstellzeit_Status: accessed-variable=RP_IF_MO_Fahrzeugabstellzeit_Status_XIX_Grundumfang_XIX_LE_TWIN.DE_MO_Fahrzeugabstellzeit_Status
            REC_RP_IF_MO_Fahrzeugabstellzeit_XIX_Grundumfang_XIX_LE_TWIN_DE_MO_Fahrzeugabstellzeit: accessed-variable=RP_IF_MO_Fahrzeugabstellzeit_XIX_Grundumfang_XIX_LE_TWIN.DE_MO_Fahrzeugabstellzeit
            REC_RP_IF_MO_HV_Auszeit_Status_XIX_Grundumfang_XIX_LE_TWIN_DE_MO_HV_Auszeit_Status: accessed-variable=RP_IF_MO_HV_Auszeit_Status_XIX_Grundumfang_XIX_LE_TWIN.DE_MO_HV_Auszeit_Status
            REC_RP_IF_MO_HV_Auszeit_XIX_Grundumfang_XIX_LE_TWIN_DE_MO_HV_Auszeit: accessed-variable=RP_IF_MO_HV_Auszeit_XIX_Grundumfang_XIX_LE_TWIN.DE_MO_HV_Auszeit
            REC_RP_IF_MO_OBD_Typ_XIX_Grundumfang_XIX_LE_TWIN_DE_MO_OBD_Typ: accessed-variable=RP_IF_MO_OBD_Typ_XIX_Grundumfang_XIX_LE_TWIN.DE_MO_OBD_Typ
            REC_RP_IF_MO_TNW_Max_Spannung_Lim_XIX_Grundumfang_XIX_LE_TWIN_DE_MO_TNW_Max_Spannung_Lim: accessed-variable=RP_IF_MO_TNW_Max_Spannung_Lim_XIX_Grundumfang_XIX_LE_TWIN.DE_MO_TNW_Max_Spannung_Lim
            REC_RP_IF_MO_TNW_Max_Strom_Lim_XIX_Grundumfang_XIX_LE_TWIN_DE_MO_TNW_Max_Strom_Lim: accessed-variable=RP_IF_MO_TNW_Max_Strom_Lim_XIX_Grundumfang_XIX_LE_TWIN.DE_MO_TNW_Max_Strom_Lim
            REC_RP_IF_MO_TNW_Min_Spannung_Lim_XIX_Grundumfang_XIX_LE_TWIN_DE_MO_TNW_Min_Spannung_Lim: accessed-variable=RP_IF_MO_TNW_Min_Spannung_Lim_XIX_Grundumfang_XIX_LE_TWIN.DE_MO_TNW_Min_Spannung_Lim
            REC_RP_IF_MO_TNW_Min_Strom_Lim_XIX_Grundumfang_XIX_LE_TWIN_DE_MO_TNW_Min_Strom_Lim: accessed-variable=RP_IF_MO_TNW_Min_Strom_Lim_XIX_Grundumfang_XIX_LE_TWIN.DE_MO_TNW_Min_Strom_Lim
            REC_RP_IF_OBD_Abs_Pedal_Pos_XIX_Grundumfang_XIX_LE_TWIN_DE_OBD_Abs_Pedal_Pos: accessed-variable=RP_IF_OBD_Abs_Pedal_Pos_XIX_Grundumfang_XIX_LE_TWIN.DE_OBD_Abs_Pedal_Pos
            REC_RP_IF_OBD_Calc_Load_Val_XIX_Grundumfang_XIX_LE_TWIN_DE_OBD_Calc_Load_Val: accessed-variable=RP_IF_OBD_Calc_Load_Val_XIX_Grundumfang_XIX_LE_TWIN.DE_OBD_Calc_Load_Val
            REC_RP_IF_OBD_ClearMem_Inhibit_XIX_Grundumfang_XIX_LE_TWIN_DE_OBD_ClearMem_Inhibit: accessed-variable=RP_IF_OBD_ClearMem_Inhibit_XIX_Grundumfang_XIX_LE_TWIN.DE_OBD_ClearMem_Inhibit
            REC_RP_IF_OBD_Driving_Cycle_XIX_Grundumfang_XIX_LE_TWIN_DE_OBD_Driving_Cycle: accessed-variable=RP_IF_OBD_Driving_Cycle_XIX_Grundumfang_XIX_LE_TWIN.DE_OBD_Driving_Cycle
            REC_RP_IF_OBD_Kaltstart_Denominator_XIX_Grundumfang_XIX_LE_TWIN_DE_OBD_Kaltstart_Denominator: accessed-variable=RP_IF_OBD_Kaltstart_Denominator_XIX_Grundumfang_XIX_LE_TWIN.DE_OBD_Kaltstart_Denominator
            REC_RP_IF_OBD_Normed_Trip_XIX_Grundumfang_XIX_LE_TWIN_DE_OBD_Normed_Trip: accessed-variable=RP_IF_OBD_Normed_Trip_XIX_Grundumfang_XIX_LE_TWIN.DE_OBD_Normed_Trip
            REC_RP_IF_OBD_Sperrung_IUMPR_XIX_Grundumfang_XIX_LE_TWIN_DE_OBD_Sperrung_IUMPR: accessed-variable=RP_IF_OBD_Sperrung_IUMPR_XIX_Grundumfang_XIX_LE_TWIN.DE_OBD_Sperrung_IUMPR
            REC_RP_IF_OBD_Sperrung_Kaltstart_Denom_XIX_Grundumfang_XIX_LE_TWIN_DE_OBD_Sperrung_Kaltstart_Denom: accessed-variable=RP_IF_OBD_Sperrung_Kaltstart_Denom_XIX_Grundumfang_XIX_LE_TWIN.DE_OBD_Sperrung_Kaltstart_Denom
            REC_RP_IF_OBD_Warm_Up_Cycle_XIX_Grundumfang_XIX_LE_TWIN_DE_OBD_Warm_Up_Cycle: accessed-variable=RP_IF_OBD_Warm_Up_Cycle_XIX_Grundumfang_XIX_LE_TWIN.DE_OBD_Warm_Up_Cycle
            REC_RP_IF_OBDProtocol_req_XIX_Grundumfang_XIX_LE_TWIN_DE_OBDProtocol_req: accessed-variable=RP_IF_OBDProtocol_req_XIX_Grundumfang_XIX_LE_TWIN.DE_OBDProtocol_req
            REC_RP_IF_SG_Airbag_01_SG_Airbag_01: accessed-variable=RP_IF_SG_Airbag_01.SG_Airbag_01
            REC_RP_IF_SG_Airbag_01_SG_Airbag_2: accessed-variable=RP_IF_SG_Airbag_01.SG_Airbag_01
            REC_RP_IF_SG_ESP_21_SG_ESP_21: accessed-variable=RP_IF_SG_ESP_21.SG_ESP_21
            REC_RP_IF_SG_ESP_21_SG_ESP_22: accessed-variable=RP_IF_SG_ESP_21.SG_ESP_21
            REC_RP_IF_SG_HVK_01_SG_HVK_01: accessed-variable=RP_IF_SG_HVK_01.SG_HVK_01
            REC_RP_IF_SG_HVK_01_SG_HVK_2: accessed-variable=RP_IF_SG_HVK_01.SG_HVK_01
            REC_RP_IF_SG_Klemmen_Status_01_SG_Klemmen_Status_01: accessed-variable=RP_IF_SG_Klemmen_Status_01.SG_Klemmen_Status_01
            REC_RP_IF_SG_Klemmen_Status_01_SG_Klemmen_Status_2: accessed-variable=RP_IF_SG_Klemmen_Status_01.SG_Klemmen_Status_01
            REC_RP_IF_SG_Motor_56_SG_Motor_56: accessed-variable=RP_IF_SG_Motor_56.SG_Motor_56
            REC_RP_IF_SG_Motor_56_SG_Motor_57: accessed-variable=RP_IF_SG_Motor_56.SG_Motor_56
            REC_RP_IF_SI_P_Mode_gueltig_XIX_Grundumfang_XIX_LE_TWIN_DE_SI_P_Mode_gueltig: accessed-variable=RP_IF_SI_P_Mode_gueltig_XIX_Grundumfang_XIX_LE_TWIN.DE_SI_P_Mode_gueltig
            REC_RP_IF_SI_P_Mode_XIX_Grundumfang_XIX_LE_TWIN_DE_SI_P_Mode: accessed-variable=RP_IF_SI_P_Mode_XIX_Grundumfang_XIX_LE_TWIN.DE_SI_P_Mode
            REC_RP_IF_UH_Jahr_XIX_Grundumfang_XIX_LE_TWIN_DE_UH_Jahr: accessed-variable=RP_IF_UH_Jahr_XIX_Grundumfang_XIX_LE_TWIN.DE_UH_Jahr
            REC_RP_IF_UH_Minute_XIX_Grundumfang_XIX_LE_TWIN_DE_UH_Minute: accessed-variable=RP_IF_UH_Minute_XIX_Grundumfang_XIX_LE_TWIN.DE_UH_Minute
            REC_RP_IF_UH_Monat_XIX_Grundumfang_XIX_LE_TWIN_DE_UH_Monat: accessed-variable=RP_IF_UH_Monat_XIX_Grundumfang_XIX_LE_TWIN.DE_UH_Monat
            REC_RP_IF_UH_Sekunde_XIX_Grundumfang_XIX_LE_TWIN_DE_UH_Sekunde: accessed-variable=RP_IF_UH_Sekunde_XIX_Grundumfang_XIX_LE_TWIN.DE_UH_Sekunde
            REC_RP_IF_UH_Stunde_XIX_Grundumfang_XIX_LE_TWIN_DE_UH_Stunde: accessed-variable=RP_IF_UH_Stunde_XIX_Grundumfang_XIX_LE_TWIN.DE_UH_Stunde
            REC_RP_IF_UH_Tag_XIX_Grundumfang_XIX_LE_TWIN_DE_UH_Tag: accessed-variable=RP_IF_UH_Tag_XIX_Grundumfang_XIX_LE_TWIN.DE_UH_Tag
            REC_RP_IF_VIN_01_MUX0x{00..02}_DE_VIN_01_MUX: accessed-variable=RP_IF_VIN_01_MUX0x{00..02}.DE_VIN_01_MUX
            REC_RP_IF_VIN_1_DE_VIN_1: accessed-variable=RP_IF_VIN_1.DE_VIN_1
            REC_RP_IF_VIN_{10..17}_DE_VIN_{10..17}: accessed-variable=RP_IF_VIN_{10..17}.DE_VIN_{10..17}
            REC_RP_IF_VIN_{2..9}_DE_VIN_{2..9}: accessed-variable=RP_IF_VIN_{2..9}.DE_VIN_{2..9}
            REC_RP_IF_WFS_IMMO_MSG4_CRC_XIX_Grundumfang_XIX_LE_TWIN_DE_WFS_IMMO_MSG4_CRC: accessed-variable=RP_IF_WFS_IMMO_MSG4_CRC_XIX_Grundumfang_XIX_LE_TWIN.DE_WFS_IMMO_MSG4_CRC
            REC_RP_IF_WFS_IMMO_MSG4_Data_{0..2}_XIX_Grundumfang_XIX_LE_TWIN_DE_WFS_IMMO_MSG4_Data_{0..2}: accessed-variable=RP_IF_WFS_IMMO_MSG4_Data_{0..2}_XIX_Grundumfang_XIX_LE_TWIN.DE_WFS_IMMO_MSG4_Data_{0..2}
            REC_RP_IF_WFS_IMMO_MSG4_Status_XIX_Grundumfang_XIX_LE_TWIN_DE_WFS_IMMO_MSG4_Status: accessed-variable=RP_IF_WFS_IMMO_MSG4_Status_XIX_Grundumfang_XIX_LE_TWIN.DE_WFS_IMMO_MSG4_Status
            REC_RP_WfsInquiryCrc_Val: accessed-variable=RP_WfsInquiryCrc.Val
            REC_RP_WfsInquiryRnd_Val: accessed-variable=RP_WfsInquiryRnd.Val
            REC_ServiceReq_Sts: accessed-variable=ServiceReq.Sts
            REC_SmpOilTEstimd_TValSts: accessed-variable=SmpOilTEstimd.TValSts
            REC_TempPerformanceIndcrDcDc_TempIndcrValSts: accessed-variable=TempPerformanceIndcrDcDc.TempIndcrValSts
            REC_TempPerformanceIndcrDcDc_TempIndcrVal: accessed-variable=TempPerformanceIndcrDcDc.TempIndcrVal
            REC_TOilCooltVolFlow_VolTarValSts: accessed-variable=TOilCooltVolFlow.VolTarValSts
            REC_CANNodeBusKnockOut_Sts: accessed-variable=CANNodeBusKnockOut.Sts
            REC_CANNodeBusKnockOutTimer_Val: accessed-variable=CANNodeBusKnockOutTimer.Val
            REC_CANNodeECUKnockOut_Sts: accessed-variable=CANNodeECUKnockOut.Sts
            REC_CANNodeECUKnockOutTimer_Val: accessed-variable=CANNodeECUKnockOutTimer.Val
            REC_Em1OffsLrng_Req: accessed-variable=Em1OffsLrng.Req
            REC_Em2OffsLrng_Req: accessed-variable=Em2OffsLrng.Req
            REC_RP_IF_MO_Eta_Verschlechterung_XIX_Grundumfang_XIX_LE_TWIN_DE_MO_Eta_Verschlechterung: accessed-variable=RP_IF_MO_Eta_Verschlechterung_XIX_Grundumfang_XIX_LE_TWIN.DE_MO_Eta_Verschlechterung
            REC_RP_IF_OBD_Eng_Cool_Temp_XIX_Grundumfang_XIX_LE_TWIN_DE_OBD_Eng_Cool_Temp_DE_OBD_Eng_Cool_Temp: accessed-variable=RP_IF_OBD_Eng_Cool_Temp_XIX_Grundumfang_XIX_LE_TWIN_DE_OBD_Eng_Cool_Temp.DE_OBD_Eng_Cool_Temp
            REC_MIError_Sts: accessed-variable=MIError.Sts
            REC_PeWtrCooltInletTEstimd_ValSts: accessed-variable=PeWtrCooltInletTEstimd.ValSts
            REC_Em1AirgapTqAddlGenr_TqValSts: accessed-variable=Em1AirgapTqAddlGenr.TqValSts
            REC_RP_IF_OBD_Minimum_Trip_DE_OBD_Minimum_Trip: accessed-variable=RP_IF_OBD_Minimum_Trip_XIX_Grundumfang_XIX_LE_TWIN.DE_OBD_Minimum_Trip
        data-send-points:
          177 x access:
            SEND_AmbDataTimestamp_Val: accessed-variable=AmbDataTimestamp.Val
            SEND_AmbTAct_TVal: accessed-variable=AmbTAct.TVal
            SEND_AmbTAct_ValSts: accessed-variable=AmbTAct.ValSts
            SEND_Clutch_Sts: accessed-variable=Clutch.Sts
            SEND_DcConnectorULim_UMaxValSts: accessed-variable=DcConnectorULim.UMaxValSts
            SEND_DcConnectorULim_UMinValSts: accessed-variable=DcConnectorULim.UMinValSts
            SEND_DrivingCycleDetected_Sts: accessed-variable=DrivingCycleDetected.Sts
            SEND_Eds1AirgapTqReq_FlgVal: accessed-variable=Eds1AirgapTqReq.FlgVal
            SEND_Eds1GenPwr_PwrValSts: accessed-variable=Eds1GenPwr.PwrValSts
            SEND_Eds1MaxPwrTot_PwrValSts: accessed-variable=Eds1MaxPwrTot.PwrValSts
            SEND_Eds1MinPwrTot_PwrValSts: accessed-variable=Eds1MinPwrTot.PwrValSts
            SEND_Eds2GenPwr_PwrValSts: accessed-variable=Eds2GenPwr.PwrValSts
            SEND_Eds2MaxPwrTot_PwrValSts: accessed-variable=Eds2MaxPwrTot.PwrValSts
            SEND_Eds2MinPwrTot_PwrValSts: accessed-variable=Eds2MinPwrTot.PwrValSts
            SEND_Em1CurrMaxLim_IMaxVal: accessed-variable=Em1CurrMaxLim.IMaxVal
            SEND_Em1CurrMinLim_IMinVal: accessed-variable=Em1CurrMinLim.IMinVal
            SEND_Em1VoltMaxLim_UMaxVal: accessed-variable=Em1VoltMaxLim.UMaxVal
            SEND_Em1VoltMaxLim_UMaxValSts: accessed-variable=Em1VoltMaxLim.UMaxValSts
            SEND_Em1VoltMinLim_UMinVal: accessed-variable=Em1VoltMinLim.UMinVal
            SEND_Em1VoltMinLim_UMinValSts: accessed-variable=Em1VoltMinLim.UMinValSts
            SEND_Em2CurrMaxLim_IMaxVal: accessed-variable=Em2CurrMaxLim.IMaxVal
            SEND_Em2CurrMinLim_IMinVal: accessed-variable=Em2CurrMinLim.IMinVal
            SEND_Em2TqLimTracCtrl_TqMaxVal: accessed-variable=Em2TqLimTracCtrl.TqMaxVal
            SEND_Em2TqLimTracCtrl_TqMinVal: accessed-variable=Em2TqLimTracCtrl.TqMinVal
            SEND_Em2VoltMaxLim_UMaxVal: accessed-variable=Em2VoltMaxLim.UMaxVal
            SEND_Em2VoltMaxLim_UMaxValSts: accessed-variable=Em2VoltMaxLim.UMaxValSts
            SEND_Em2VoltMinLim_UMinVal: accessed-variable=Em2VoltMinLim.UMinVal
            SEND_Em2VoltMinLim_UMinValSts: accessed-variable=Em2VoltMinLim.UMinValSts
            SEND_IceCooltTAct_TVal: accessed-variable=IceCooltTAct.TVal
            SEND_IceCooltTAct_ValSts: accessed-variable=IceCooltTAct.ValSts
            SEND_Mileage_ValSts: accessed-variable=Mileage.ValSts
            SEND_NetIoMgr10msEvents_Status: accessed-variable=NetIoMgr10msEvents.Status
            SEND_OBDClearMemInhibit_FlgVal: accessed-variable=OBDClearMemInhibit.FlgVal
            SEND_OilCooltTSw_TValSts: accessed-variable=OilCooltTSw.TValSts
            SEND_OilCooltVolFlowCalcd_VolFlowValSts: accessed-variable=OilCooltVolFlowCalcd.VolFlowValSts
            SEND_PECInIf_cirmWhl_VW_PECInIf_cirmWhl_VW: accessed-variable=PECInIf_cirmWhl_VW.PECInIf_cirmWhl_VW
            SEND_PECInIf_noToothWhlSens_VW_PECInIf_noToothWhlSens_VW: accessed-variable=PECInIf_noToothWhlSens_VW.PECInIf_noToothWhlSens_VW
            SEND_PECInIf_stClu_VW_PECInIf_stClu_VW: accessed-variable=PECInIf_stClu_VW.PECInIf_stClu_VW
            SEND_PECInIf_stCluAvl_VW_PECInIf_stCluAvl_VW: accessed-variable=PECInIf_stCluAvl_VW.PECInIf_stCluAvl_VW
            SEND_PP_DrvgRdy_Sts: accessed-variable=PP_DrvgRdy.Sts
            SEND_ProductionModeActv_Sts: accessed-variable=ProductionModeActv.Sts
            SEND_ProductionModeValid_Sts: accessed-variable=ProductionModeValid.Sts
            SEND_RlySts_StsVal: accessed-variable=RlySts.StsVal
            SEND_SP_DrivePermissionRequest_Val: accessed-variable=SP_DrivePermissionRequest.Val
            SEND_SP_EM2_Fehler_AE_DE_EM2_Fehler_AE: accessed-variable=SP_IF_EM2_Fehler_AE.DE_EM2_Fehler_AE
            SEND_SP_IF_EM1_AktiveEntladung_XIX_Grundumfang_XIX_LE_TWIN_DE_EM1_AktiveEntladung: accessed-variable=SP_IF_EM1_AktiveEntladung_XIX_Grundumfang_XIX_LE_TWIN.DE_EM1_AktiveEntladung
            SEND_SP_IF_EM1_AnlernenElMotor_Anf_XIX_Grundumfang_XIX_LE_TWIN_DE_EM1_AnlernenElMotor_Anf: accessed-variable=SP_IF_EM1_AnlernenElMotor_Anf_XIX_Grundumfang_XIX_LE_TWIN.DE_EM1_AnlernenElMotor_Anf
            SEND_SP_IF_EM1_EM_SollVolumenstrom_DE_EM1_EM_SollVolumenstrom: accessed-variable=SP_IF_EM1_EM_SollVolumenstrom.DE_EM1_EM_SollVolumenstrom
            SEND_SP_IF_EM1_Fehler_AE_XIX_Grundumfang_XIX_LE_TWIN_DE_EM1_Fehler_AE: accessed-variable=SP_IF_EM1_Fehler_AE_XIX_Grundumfang_XIX_LE_TWIN.DE_EM1_Fehler_AE
            SEND_SP_IF_EM1_Fehler_ElAntriebFreilauf_XIX_Grundumfang_XIX_LE_TWIN_DE_EM1_Fehler_ElAntriebFreilauf: accessed-variable=SP_IF_EM1_Fehler_ElAntriebFreilauf_XIX_Grundumfang_XIX_LE_TWIN.DE_EM1_Fehler_ElAntriebFreilauf
            SEND_SP_IF_EM1_Fehler_Leistungsred_DE_EM1_Fehler_Leistungsred: accessed-variable=SP_IF_EM1_Fehler_Leistungsred.DE_EM1_Fehler_Leistungsred
            SEND_SP_IF_EM1_Fehlerlampe_Anf_XIX_Grundumfang_XIX_LE_TWIN_DE_EM1_Fehlerlampe_Anf: accessed-variable=SP_IF_EM1_Fehlerlampe_Anf_XIX_Grundumfang_XIX_LE_TWIN.DE_EM1_Fehlerlampe_Anf
            SEND_SP_IF_EM1_Freigabe_Info_WFS_XIX_Grundumfang_XIX_LE_TWIN_DE_EM1_Freigabe_Info_WFS: accessed-variable=SP_IF_EM1_Freigabe_Info_WFS_XIX_Grundumfang_XIX_LE_TWIN.DE_EM1_Freigabe_Info_WFS
            SEND_SP_IF_EM1_Freigabe_Verfallsinfo_WFS_XIX_Grundumfang_XIX_LE_TWIN_DE_EM1_Freigabe_Verfallsinfo_WFS: accessed-variable=SP_IF_EM1_Freigabe_Verfallsinfo_WFS_XIX_Grundumfang_XIX_LE_TWIN.DE_EM1_Freigabe_Verfallsinfo_WFS
            SEND_SP_IF_EM1_Generator_Moment_XIX_Grundumfang_XIX_LE_TWIN_DE_EM1_Generator_Moment: accessed-variable=SP_IF_EM1_Generator_Moment_XIX_Grundumfang_XIX_LE_TWIN.DE_EM1_Generator_Moment
            SEND_SP_IF_EM1_IsoFehler_XIX_Grundumfang_XIX_LE_TWIN_DE_EM1_IsoFehler: accessed-variable=SP_IF_EM1_IsoFehler_XIX_Grundumfang_XIX_LE_TWIN.DE_EM1_IsoFehler
            SEND_SP_IF_EM1_IsoZustand_XIX_Grundumfang_XIX_LE_TWIN_DE_EM1_IsoZustand: accessed-variable=SP_IF_EM1_IsoZustand_XIX_Grundumfang_XIX_LE_TWIN.DE_EM1_IsoZustand
            SEND_SP_IF_EM1_IstStrom_DE_EM1_IstStrom: accessed-variable=SP_IF_EM1_IstStrom.DE_EM1_IstStrom
            SEND_SP_IF_EM1_Kuehlung_EM_Anf_02_XIX_Grundumfang_XIX_LE_TWIN_DE_EM1_Kuehlung_EM_Anf_02: accessed-variable=SP_IF_EM1_Kuehlung_EM_Anf_02_XIX_Grundumfang_XIX_LE_TWIN.DE_EM1_Kuehlung_EM_Anf_02
            SEND_SP_IF_EM1_Max_LeistungMech_Sockel_XIX_Grundumfang_XIX_LE_TWIN_DE_EM1_Max_LeistungMech_Sockel: accessed-variable=SP_IF_EM1_Max_LeistungMech_Sockel_XIX_Grundumfang_XIX_LE_TWIN.DE_EM1_Max_LeistungMech_Sockel
            SEND_SP_IF_EM1_Max_MechLeistung_nom_XIX_Grundumfang_XIX_LE_TWIN_DE_EM1_Max_MechLeistung_nom: accessed-variable=SP_IF_EM1_Max_MechLeistung_nom_XIX_Grundumfang_XIX_LE_TWIN.DE_EM1_Max_MechLeistung_nom
            SEND_SP_IF_EM1_Max_Moment_nom_XIX_Grundumfang_XIX_LE_TWIN_DE_EM1_Max_Moment_nom: accessed-variable=SP_IF_EM1_Max_Moment_nom_XIX_Grundumfang_XIX_LE_TWIN.DE_EM1_Max_Moment_nom
            SEND_SP_IF_EM1_Max_Moment_Sockel_XIX_Grundumfang_XIX_LE_TWIN_DE_EM1_Max_Moment_Sockel: accessed-variable=SP_IF_EM1_Max_Moment_Sockel_XIX_Grundumfang_XIX_LE_TWIN.DE_EM1_Max_Moment_Sockel
            SEND_SP_IF_EM1_MaxZul_Drehzahl_XIX_Grundumfang_XIX_LE_TWIN_DE_EM1_MaxZul_Drehzahl: accessed-variable=SP_IF_EM1_MaxZul_Drehzahl_XIX_Grundumfang_XIX_LE_TWIN.DE_EM1_MaxZul_Drehzahl
            SEND_SP_IF_EM1_Min_LeistungMech_Sockel_XIX_Grundumfang_XIX_LE_TWIN_DE_EM1_Min_LeistungMech_Sockel: accessed-variable=SP_IF_EM1_Min_LeistungMech_Sockel_XIX_Grundumfang_XIX_LE_TWIN.DE_EM1_Min_LeistungMech_Sockel
            SEND_SP_IF_EM1_Min_Moment_Sockel_XIX_Grundumfang_XIX_LE_TWIN_DE_EM1_Min_Moment_Sockel: accessed-variable=SP_IF_EM1_Min_Moment_Sockel_XIX_Grundumfang_XIX_LE_TWIN.DE_EM1_Min_Moment_Sockel
            SEND_SP_IF_EM1_OBD_Lampe_Anf_XIX_Grundumfang_XIX_LE_TWIN_DE_EM1_OBD_Lampe_Anf: accessed-variable=SP_IF_EM1_OBD_Lampe_Anf_XIX_Grundumfang_XIX_LE_TWIN.DE_EM1_OBD_Lampe_Anf
            SEND_SP_IF_EM1_Parken_WFS_Status_XIX_Grundumfang_XIX_LE_TWIN_DE_EM1_Parken_WFS_Status: accessed-variable=SP_IF_EM1_Parken_WFS_Status_XIX_Grundumfang_XIX_LE_TWIN.DE_EM1_Parken_WFS_Status
            SEND_SP_IF_EM1_PerfInd_MaxLeistung_XIX_Grundumfang_XIX_LE_TWIN_DE_EM1_PerfInd_MaxLeistung: accessed-variable=SP_IF_EM1_PerfInd_MaxLeistung_XIX_Grundumfang_XIX_LE_TWIN.DE_EM1_PerfInd_MaxLeistung
            SEND_SP_IF_EM1_PerfInd_MaxMoment_XIX_Grundumfang_XIX_LE_TWIN_DE_EM1_PerfInd_MaxMoment: accessed-variable=SP_IF_EM1_PerfInd_MaxMoment_XIX_Grundumfang_XIX_LE_TWIN.DE_EM1_PerfInd_MaxMoment
            SEND_SP_IF_EM1_PerfInd_Temperatur_XIX_Grundumfang_XIX_LE_TWIN_DE_EM1_PerfInd_Temperatur: accessed-variable=SP_IF_EM1_PerfInd_Temperatur_XIX_Grundumfang_XIX_LE_TWIN.DE_EM1_PerfInd_Temperatur
            SEND_SP_IF_EM1_PWR_SollVolumenstrom_XIX_Grundumfang_XIX_LE_TWIN_DE_EM1_PWR_SollVolumenstrom: accessed-variable=SP_IF_EM1_PWR_SollVolumenstrom_XIX_Grundumfang_XIX_LE_TWIN.DE_EM1_PWR_SollVolumenstrom
            SEND_SP_IF_EM1_Rekuperation_Ueberlauf_XIX_Grundumfang_XIX_LE_TWIN_DE_EM1_Rekuperation_Ueberlauf: accessed-variable=SP_IF_EM1_Rekuperation_Ueberlauf_XIX_Grundumfang_XIX_LE_TWIN.DE_EM1_Rekuperation_Ueberlauf
            SEND_SP_IF_EM1_Rekuperation_XIX_Grundumfang_XIX_LE_TWIN_DE_EM1_Rekuperation: accessed-variable=SP_IF_EM1_Rekuperation_XIX_Grundumfang_XIX_LE_TWIN.DE_EM1_Rekuperation
            SEND_SP_IF_EM1_RtmWarnTempEM_XIX_Grundumfang_XIX_LE_TWIN_DE_EM1_RtmWarnTempEM: accessed-variable=SP_IF_EM1_RtmWarnTempEM_XIX_Grundumfang_XIX_LE_TWIN.DE_EM1_RtmWarnTempEM
            SEND_SP_IF_EM1_RtmWarnTempPWR_XIX_Grundumfang_XIX_LE_TWIN_DE_EM1_RtmWarnTempPWR: accessed-variable=SP_IF_EM1_RtmWarnTempPWR_XIX_Grundumfang_XIX_LE_TWIN.DE_EM1_RtmWarnTempPWR
            SEND_SP_IF_EM1_RtmWarnUeberdrehzahl_XIX_Grundumfang_XIX_LE_TWIN_DE_EM1_RtmWarnUeberdrehzahl: accessed-variable=SP_IF_EM1_RtmWarnUeberdrehzahl_XIX_Grundumfang_XIX_LE_TWIN.DE_EM1_RtmWarnUeberdrehzahl
            SEND_SP_IF_EM1_RtmWarnUeberstrom_XIX_Grundumfang_XIX_LE_TWIN_DE_EM1_RtmWarnUeberstrom: accessed-variable=SP_IF_EM1_RtmWarnUeberstrom_XIX_Grundumfang_XIX_LE_TWIN.DE_EM1_RtmWarnUeberstrom
            SEND_SP_IF_EM1_SmpOilTEstimd_XIX_Grundumfang_XIX_LE_TWIN_DE_EM1_SmpOilTEstimd: accessed-variable=SP_IF_EM1_SmpOilTEstimd_XIX_Grundumfang_XIX_LE_TWIN.DE_EM1_SmpOilTEstimd
            SEND_SP_IF_EM1_SollOelVolumenstrom_DE_EM1_SollOelVolumenstrom: accessed-variable=SP_IF_EM1_SollOelVolumenstrom.DE_EM1_SollOelVolumenstrom
            SEND_SP_IF_EM1_SollVorlauftemperatur_XIX_Grundumfang_XIX_LE_TWIN_DE_EM1_SollVorlauftemperatur: accessed-variable=SP_IF_EM1_SollVorlauftemperatur_XIX_Grundumfang_XIX_LE_TWIN.DE_EM1_SollVorlauftemperatur
            SEND_SP_IF_EM1_Sperr_Info_WFS_XIX_Grundumfang_XIX_LE_TWIN_DE_EM1_Sperr_Info_WFS: accessed-variable=SP_IF_EM1_Sperr_Info_WFS_XIX_Grundumfang_XIX_LE_TWIN.DE_EM1_Sperr_Info_WFS
            SEND_SP_IF_EM1_Status_EoHVL_XIX_Grundumfang_XIX_LE_TWIN_DE_EM1_Status_EoHVL: accessed-variable=SP_IF_EM1_Status_EoHVL_XIX_Grundumfang_XIX_LE_TWIN.DE_EM1_Status_EoHVL
            SEND_SP_IF_EM1_Status_Spgfreiheit_XIX_Grundumfang_XIX_LE_TWIN_DE_EM1_Status_Spgfreiheit: accessed-variable=SP_IF_EM1_Status_Spgfreiheit_XIX_Grundumfang_XIX_LE_TWIN.DE_EM1_Status_Spgfreiheit
            SEND_SP_IF_EM1_Temperatur_EM_DE_EM1_Temperatur_EM: accessed-variable=SP_IF_EM1_Temperatur_EM.DE_EM1_Temperatur_EM
            SEND_SP_IF_EM1_Temperatur_PWR_XIX_Grundumfang_XIX_LE_TWIN_DE_EM1_Temperatur_PWR: accessed-variable=SP_IF_EM1_Temperatur_PWR_XIX_Grundumfang_XIX_LE_TWIN.DE_EM1_Temperatur_PWR
            SEND_SP_IF_EM1_Verbrauch_Ueberlauf_XIX_Grundumfang_XIX_LE_TWIN_DE_EM1_Verbrauch_Ueberlauf: accessed-variable=SP_IF_EM1_Verbrauch_Ueberlauf_XIX_Grundumfang_XIX_LE_TWIN.DE_EM1_Verbrauch_Ueberlauf
            SEND_SP_IF_EM1_Verbrauch_XIX_Grundumfang_XIX_LE_TWIN_DE_EM1_Verbrauch: accessed-variable=SP_IF_EM1_Verbrauch_XIX_Grundumfang_XIX_LE_TWIN.DE_EM1_Verbrauch
            SEND_SP_IF_EM1_Warnlampe_Anf_XIX_Grundumfang_XIX_LE_TWIN_DE_EM1_Warnlampe_Anf: accessed-variable=SP_IF_EM1_Warnlampe_Anf_XIX_Grundumfang_XIX_LE_TWIN.DE_EM1_Warnlampe_Anf
            SEND_SP_IF_EM2_AktiveEntladung_DE_EM2_AktiveEntladung: accessed-variable=SP_IF_EM2_AktiveEntladung.DE_EM2_AktiveEntladung
            SEND_SP_IF_EM2_AnlernenElMotor_Anf_XIX_Grundumfang_XIX_LE_TWIN_DE_EM2_AnlernenElMotor_Anf: accessed-variable=SP_IF_EM2_AnlernenElMotor_Anf_XIX_Grundumfang_XIX_LE_TWIN.DE_EM2_AnlernenElMotor_Anf
            SEND_SP_IF_EM2_AR_aktiv_XIX_Grundumfang_XIX_LE_TWIN_DE_EM2_AR_aktiv: accessed-variable=SP_IF_EM2_AR_aktiv_XIX_Grundumfang_XIX_LE_TWIN.DE_EM2_AR_aktiv
            SEND_SP_IF_EM2_EM_SollVolumenstrom_DE_EM2_EM_SollVolumenstrom: accessed-variable=SP_IF_EM2_EM_SollVolumenstrom.DE_EM2_EM_SollVolumenstrom
            SEND_SP_IF_EM2_Fehler_ElAntriebFreilauf_XIX_Grundumfang_XIX_LE_TWIN_DE_EM2_Fehler_ElAntriebFreilauf: accessed-variable=SP_IF_EM2_Fehler_ElAntriebFreilauf_XIX_Grundumfang_XIX_LE_TWIN.DE_EM2_Fehler_ElAntriebFreilauf
            SEND_SP_IF_EM2_Fehler_Leistungsred_DE_EM2_Fehler_Leistungsred: accessed-variable=SP_IF_EM2_Fehler_Leistungsred.DE_EM2_Fehler_Leistungsred
            SEND_SP_IF_EM2_Fehlerlampe_Anf_XIX_Grundumfang_XIX_LE_TWIN_DE_EM2_Fehlerlampe_Anf: accessed-variable=SP_IF_EM2_Fehlerlampe_Anf_XIX_Grundumfang_XIX_LE_TWIN.DE_EM2_Fehlerlampe_Anf
            SEND_SP_IF_EM2_Generator_Moment_XIX_Grundumfang_XIX_LE_TWIN_DE_EM2_Generator_Moment: accessed-variable=SP_IF_EM2_Generator_Moment_XIX_Grundumfang_XIX_LE_TWIN.DE_EM2_Generator_Moment
            SEND_SP_IF_EM2_Max_LeistungMech_Sockel_DE_EM2_Max_LeistungMech_Sockel: accessed-variable=SP_IF_EM2_Max_LeistungMech_Sockel.DE_EM2_Max_LeistungMech_Sockel
            SEND_SP_IF_EM2_Max_MechLeistung_nom_XIX_Grundumfang_XIX_LE_TWIN_DE_EM2_Max_MechLeistung_nom: accessed-variable=SP_IF_EM2_Max_MechLeistung_nom_XIX_Grundumfang_XIX_LE_TWIN.DE_EM2_Max_MechLeistung_nom
            SEND_SP_IF_EM2_Max_Moment_nom_XIX_Grundumfang_XIX_LE_TWIN_DE_EM2_Max_Moment_nom: accessed-variable=SP_IF_EM2_Max_Moment_nom_XIX_Grundumfang_XIX_LE_TWIN.DE_EM2_Max_Moment_nom
            SEND_SP_IF_EM2_Max_Moment_Sockel_DE_EM2_Max_Moment_Sockel: accessed-variable=SP_IF_EM2_Max_Moment_Sockel.DE_EM2_Max_Moment_Sockel
            SEND_SP_IF_EM2_MaxZul_Drehzahl_XIX_Grundumfang_XIX_LE_TWIN_DE_EM2_MaxZul_Drehzahl: accessed-variable=SP_IF_EM2_MaxZul_Drehzahl_XIX_Grundumfang_XIX_LE_TWIN.DE_EM2_MaxZul_Drehzahl
            SEND_SP_IF_EM2_Min_LeistungMech_Sockel_DE_EM2_Min_LeistungMech_Sockel: accessed-variable=SP_IF_EM2_Min_LeistungMech_Sockel.DE_EM2_Min_LeistungMech_Sockel
            SEND_SP_IF_EM2_Min_Moment_Sockel_DE_EM2_Min_Moment_Sockel: accessed-variable=SP_IF_EM2_Min_Moment_Sockel.DE_EM2_Min_Moment_Sockel
            SEND_SP_IF_EM2_OBD_Lampe_Anf_XIX_Grundumfang_XIX_LE_TWIN_DE_EM2_OBD_Lampe_Anf: accessed-variable=SP_IF_EM2_OBD_Lampe_Anf_XIX_Grundumfang_XIX_LE_TWIN.DE_EM2_OBD_Lampe_Anf
            SEND_SP_IF_EM2_PerfInd_MaxLeistung_XIX_Grundumfang_XIX_LE_TWIN_DE_EM2_PerfInd_MaxLeistung: accessed-variable=SP_IF_EM2_PerfInd_MaxLeistung_XIX_Grundumfang_XIX_LE_TWIN.DE_EM2_PerfInd_MaxLeistung
            SEND_SP_IF_EM2_PerfInd_MaxMoment_XIX_Grundumfang_XIX_LE_TWIN_DE_EM2_PerfInd_MaxMoment: accessed-variable=SP_IF_EM2_PerfInd_MaxMoment_XIX_Grundumfang_XIX_LE_TWIN.DE_EM2_PerfInd_MaxMoment
            SEND_SP_IF_EM2_PerfInd_Temperatur_XIX_Grundumfang_XIX_LE_TWIN_DE_EM2_PerfInd_Temperatur: accessed-variable=SP_IF_EM2_PerfInd_Temperatur_XIX_Grundumfang_XIX_LE_TWIN.DE_EM2_PerfInd_Temperatur
            SEND_SP_IF_EM2_PWR_SollVolumenstrom_XIX_Grundumfang_XIX_LE_TWIN_DE_EM2_PWR_SollVolumenstrom: accessed-variable=SP_IF_EM2_PWR_SollVolumenstrom_XIX_Grundumfang_XIX_LE_TWIN.DE_EM2_PWR_SollVolumenstrom
            SEND_SP_IF_EM2_Rekuperation_Ueberlauf_XIX_Grundumfang_XIX_LE_TWIN_DE_EM2_Rekuperation_Ueberlauf: accessed-variable=SP_IF_EM2_Rekuperation_Ueberlauf_XIX_Grundumfang_XIX_LE_TWIN.DE_EM2_Rekuperation_Ueberlauf
            SEND_SP_IF_EM2_Rekuperation_XIX_Grundumfang_XIX_LE_TWIN_DE_EM2_Rekuperation: accessed-variable=SP_IF_EM2_Rekuperation_XIX_Grundumfang_XIX_LE_TWIN.DE_EM2_Rekuperation
            SEND_SP_IF_EM2_RtmWarnTempEM_XIX_Grundumfang_XIX_LE_TWIN_DE_EM2_RtmWarnTempEM: accessed-variable=SP_IF_EM2_RtmWarnTempEM_XIX_Grundumfang_XIX_LE_TWIN.DE_EM2_RtmWarnTempEM
            SEND_SP_IF_EM2_RtmWarnTempPWR_XIX_Grundumfang_XIX_LE_TWIN_DE_EM2_RtmWarnTempPWR: accessed-variable=SP_IF_EM2_RtmWarnTempPWR_XIX_Grundumfang_XIX_LE_TWIN.DE_EM2_RtmWarnTempPWR
            SEND_SP_IF_EM2_RtmWarnUeberdrehzahl_XIX_Grundumfang_XIX_LE_TWIN_DE_EM2_RtmWarnUeberdrehzahl: accessed-variable=SP_IF_EM2_RtmWarnUeberdrehzahl_XIX_Grundumfang_XIX_LE_TWIN.DE_EM2_RtmWarnUeberdrehzahl
            SEND_SP_IF_EM2_RtmWarnUeberstrom_XIX_Grundumfang_XIX_LE_TWIN_DE_EM2_RtmWarnUeberstrom: accessed-variable=SP_IF_EM2_RtmWarnUeberstrom_XIX_Grundumfang_XIX_LE_TWIN.DE_EM2_RtmWarnUeberstrom
            SEND_SP_IF_EM2_SollVorlauftemperatur_XIX_Grundumfang_XIX_LE_TWIN_DE_EM2_SollVorlauftemperatur: accessed-variable=SP_IF_EM2_SollVorlauftemperatur_XIX_Grundumfang_XIX_LE_TWIN.DE_EM2_SollVorlauftemperatur
            SEND_SP_IF_EM2_Status_EoHVL_DE_EM2_Status_EoHVL: accessed-variable=SP_IF_EM2_Status_EoHVL.DE_EM2_Status_EoHVL
            SEND_SP_IF_EM2_Status_Spgfreiheit_DE_EM2_Status_Spgfreiheit: accessed-variable=SP_IF_EM2_Status_Spgfreiheit.DE_EM2_Status_Spgfreiheit
            SEND_SP_IF_EM2_Temperatur_EM_DE_EM2_Temperatur_EM: accessed-variable=SP_IF_EM2_Temperatur_EM.DE_EM2_Temperatur_EM
            SEND_SP_IF_EM2_Temperatur_PWR_XIX_Grundumfang_XIX_LE_TWIN_DE_EM2_Temperatur_PWR: accessed-variable=SP_IF_EM2_Temperatur_PWR_XIX_Grundumfang_XIX_LE_TWIN.DE_EM2_Temperatur_PWR
            SEND_SP_IF_EM2_Verbrauch_Ueberlauf_XIX_Grundumfang_XIX_LE_TWIN_DE_EM2_Verbrauch_Ueberlauf: accessed-variable=SP_IF_EM2_Verbrauch_Ueberlauf_XIX_Grundumfang_XIX_LE_TWIN.DE_EM2_Verbrauch_Ueberlauf
            SEND_SP_IF_EM2_Verbrauch_XIX_Grundumfang_XIX_LE_TWIN_DE_EM2_Verbrauch: accessed-variable=SP_IF_EM2_Verbrauch_XIX_Grundumfang_XIX_LE_TWIN.DE_EM2_Verbrauch
            SEND_SP_IF_EM2_Warnlampe_Anf_XIX_Grundumfang_XIX_LE_TWIN_DE_EM2_Warnlampe_Anf: accessed-variable=SP_IF_EM2_Warnlampe_Anf_XIX_Grundumfang_XIX_LE_TWIN.DE_EM2_Warnlampe_Anf
            SEND_SP_IF_EMotor_01_Abschaltstufe_XIX_Grundumfang_XIX_LE_TWIN_DE_EMotor_01_Abschaltstufe: accessed-variable=SP_IF_EMotor_01_Abschaltstufe_XIX_Grundumfang_XIX_LE_TWIN.DE_EMotor_01_Abschaltstufe
            SEND_SP_IF_EMotor_01_KD_Fehler_XIX_Grundumfang_XIX_LE_TWIN_DE_EMotor_01_KD_Fehler: accessed-variable=SP_IF_EMotor_01_KD_Fehler_XIX_Grundumfang_XIX_LE_TWIN.DE_EMotor_01_KD_Fehler
            SEND_SP_IF_EMotor_01_Transport_Mode_XIX_Grundumfang_XIX_LE_TWIN_DE_EMotor_01_Transport_Mode: accessed-variable=SP_IF_EMotor_01_Transport_Mode_XIX_Grundumfang_XIX_LE_TWIN.DE_EMotor_01_Transport_Mode
            SEND_SP_IF_KN_EMotor_01_BusKnockOut_XIX_Grundumfang_XIX_LE_TWIN_DE_KN_EMotor_01_BusKnockOut: accessed-variable=SP_IF_KN_EMotor_01_BusKnockOut_XIX_Grundumfang_XIX_LE_TWIN.DE_KN_EMotor_01_BusKnockOut
            SEND_SP_IF_KN_EMotor_01_BusKnockOutTimer_XIX_Grundumfang_XIX_LE_TWIN_DE_KN_EMotor_01_BusKnockOutTimer: accessed-variable=SP_IF_KN_EMotor_01_BusKnockOutTimer_XIX_Grundumfang_XIX_LE_TWIN.DE_KN_EMotor_01_BusKnockOutTimer
            SEND_SP_IF_KN_EMotor_01_ECUKnockOut_XIX_Grundumfang_XIX_LE_TWIN_DE_KN_EMotor_01_ECUKnockOut: accessed-variable=SP_IF_KN_EMotor_01_ECUKnockOut_XIX_Grundumfang_XIX_LE_TWIN.DE_KN_EMotor_01_ECUKnockOut
            SEND_SP_IF_KN_EMotor_01_ECUKnockOutTimer_XIX_Grundumfang_XIX_LE_TWIN_DE_KN_EMotor_01_ECUKnockOutTimer: accessed-variable=SP_IF_KN_EMotor_01_ECUKnockOutTimer_XIX_Grundumfang_XIX_LE_TWIN.DE_KN_EMotor_01_ECUKnockOutTimer
            SEND_SP_IF_LE1_Indc_StChk_XIX_Grundumfang_XIX_LE_TWIN_DE_LE1_Indc_StChk: accessed-variable=SP_IF_LE1_Indc_StChk_XIX_Grundumfang_XIX_LE_TWIN.DE_LE1_Indc_StChk
            SEND_SP_IF_LE1_Indc_StFail_XIX_Grundumfang_XIX_LE_TWIN_DE_LE1_Indc_StFail: accessed-variable=SP_IF_LE1_Indc_StFail_XIX_Grundumfang_XIX_LE_TWIN.DE_LE1_Indc_StFail
            SEND_SP_IF_NM_EM1_01_CBV_AWB_XIX_Grundumfang_XIX_LE_TWIN_DE_NM_EMotor_01_CBV_AWB: accessed-variable=SP_IF_NM_EM1_01_CBV_AWB_XIX_Grundumfang_XIX_LE_TWIN.DE_NM_EMotor_01_CBV_AWB
            SEND_SP_IF_NM_EMotor_01_Wakeup_XIX_Grundumfang_XIX_LE_TWIN_DE_NM_EMotor_01_Wakeup: accessed-variable=SP_IF_NM_EMotor_01_Wakeup_XIX_Grundumfang_XIX_LE_TWIN.DE_NM_EMotor_01_Wakeup
            SEND_SP_IF_OBDProtocol_LE1_XIX_Grundumfang_XIX_LE_TWIN_DE_OBDProtocol_LE1: accessed-variable=SP_IF_OBDProtocol_LE1_XIX_Grundumfang_XIX_LE_TWIN.DE_OBDProtocol_LE1
            SEND_SP_IF_SG_EM1_01_SG_EM1_01: accessed-variable=SP_IF_SG_EM1_01.SG_EM1_01
            SEND_SP_IF_SG_EM2_01_SG_EM2_01: accessed-variable=SP_IF_SG_EM2_01.SG_EM2_01
            SEND_SP_IF_TNW_IstLeistung_Prim_DE_TNW_IstLeistung_Prim: accessed-variable=SP_IF_TNW_IstLeistung_Prim_XIX_Grundumfang_XIX_LE_TWIN.DE_TNW_IstLeistung_Prim
            SEND_SP_IF_TNW_Max_Leistung_XIX_Grundumfang_XIX_LE_TWIN_DE_TNW_Max_Leistung: accessed-variable=SP_IF_TNW_Max_Leistung_XIX_Grundumfang_XIX_LE_TWIN.DE_TNW_Max_Leistung
            SEND_SP_IF_TNW_Min_Leistung_DE_TNW_Min_Leistung: accessed-variable=SP_IF_TNW_Min_Leistung.DE_TNW_Min_Leistung
            SEND_SP_IF_TNW_VerlustLeistung_XIX_Grundumfang_XIX_LE_TWIN_DE_TNW_VerlustLeistung: accessed-variable=SP_IF_TNW_VerlustLeistung_XIX_Grundumfang_XIX_LE_TWIN.DE_TNW_VerlustLeistung
            SEND_SP_IF_WFS_MSG4_CRC_XIX_Grundumfang_XIX_LE_TWIN_DE_WFS_MSG4_CRC: accessed-variable=SP_IF_WFS_MSG4_CRC_XIX_Grundumfang_XIX_LE_TWIN.DE_WFS_MSG4_CRC
            SEND_SP_IF_WFS_MSG4_RND_XIX_Grundumfang_XIX_LE_TWIN_DE_WFS_MSG4_RND: accessed-variable=SP_IF_WFS_MSG4_RND_XIX_Grundumfang_XIX_LE_TWIN.DE_WFS_MSG4_RND
            SEND_SP_IfVinMux_Sts: accessed-variable=SP_IfVinMux.Sts
            SEND_SP_IfVinMux_VinVal: accessed-variable=SP_IfVinMux.VinVal
            SEND_SP_ImoCordAuthPromptWfs_StsVal: accessed-variable=SP_ImoCordAuthPromptWfs.StsVal
            SEND_SP_KL15TranSt_Sts: accessed-variable=SP_KL15TranSt.Sts
            SEND_SP_ObdAccrPedalPos_ValSts: accessed-variable=SP_ObdAccrPedalPos.ValSts
            SEND_SP_ObdCalcLoad_ValSts: accessed-variable=SP_ObdCalcLoad.ValSts
            SEND_SP_SpecialState_Val: accessed-variable=SP_SpecialState.Val
            SEND_SP_WfsImmoMsg4_CrcVal: accessed-variable=SP_WfsImmoMsg4.CrcVal
            SEND_SP_WfsImmoMsg4_D{0..3}Val: accessed-variable=SP_WfsImmoMsg4.D{0..3}Val
            SEND_SP_WfsImmoMsg4_StsVal: accessed-variable=SP_WfsImmoMsg4.StsVal
            SEND_ToothNr_NrVal: accessed-variable=ToothNr.NrVal
            SEND_VehTiOff_TiValSts: accessed-variable=VehTiOff.TiValSts
            SEND_VehVAct_QBit: accessed-variable=VehVAct.QBit
            SEND_WarmUpCycleDetected_Sts: accessed-variable=WarmUpCycleDetected.Sts
            SEND_WtrCoolt_StsVal: accessed-variable=WtrCoolt.StsVal
            SEND_WtrCooltInlTAct_TVal: accessed-variable=WtrCooltInlTAct.TVal
            SEND_WtrCooltInlVolFlowAct_ValSts: accessed-variable=WtrCooltInlVolFlowAct.ValSts
            SEND_WtrCooltInlVolFlowAct_VolVal: accessed-variable=WtrCooltInlVolFlowAct.VolVal
            SEND_Em1EffDegrLoadMin_Val: accessed-variable=Em1EffDegrLoadMin.Val
            SEND_EngSpd_ValSts: accessed-variable=EngSpd.ValSts
            SEND_ObdNormTrip_FlgVal: accessed-variable=ObdNormTrip.FlgVal
            SEND_ObdSperrung_FlgVal: accessed-variable=ObdSperrung.FlgVal
            SEND_OBDSperrungKaltstartDenom_FlgVal: accessed-variable=OBDSperrungKaltstartDenom.FlgVal
            SEND_ObdKaltstartDenominator_FlgVal: accessed-variable=ObdKaltstartDenominator.FlgVal
            SEND_IceSpdAct_SpdVal: accessed-variable=IceSpdAct.SpdVal
            SEND_EngCoolantT_ValSts: accessed-variable=EngCoolantT.ValSts
            SEND_IF_LE1_MI_related_Error_Status_DE_LE1_MI_related_Error_Status: accessed-variable=SP_IF_LE1_MI_related_Error_Status.DE_LE1_MI_related_Error_Status
            SEND_NetIoMgr250msEvents_Status: accessed-variable=NetIoMgr250msEvents.Status
            SEND_EngCooltTQBit_ValSts: accessed-variable=EngCooltTQBit.ValSts
            SEND_WtrCooltStatus_ValSts: accessed-variable=WtrCooltStatus.ValSts
            SEND_ObdMinimumTrip_FlgVal: accessed-variable=ObdMinimumTrip.FlgVal
        8 x sync call:
          SC_DiagnosticInfo_BusOffStatus_GetEventStatus: operation=DiagnosticInfo_BusOffStatus.GetEventStatus
          SC_DiagnosticInfo_GlobalTimeoutStatus_GetEventStatus: operation=DiagnosticInfo_GlobalTimeoutStatus.GetEventStatus
          SC_DiagnosticInfo_Motor57_GetEventStatus: operation=DiagnosticInfo_Motor57.GetEventStatus
          SC_DiagnosticInfo_CluEng_01_GetEventStatus: operation=DiagnosticInfo_CluEng_01.GetEventStatus
          SC_DiagnosticInfo_Motor_07_GetEventStatus: operation=DiagnosticInfo_Motor_07.GetEventStatus
          SC_DiagnosticInfo_Motor_31_GetEventStatus: operation=DiagnosticInfo_Motor_31.GetEventStatus
          SC_DiagnosticInfo_Motor_54_GetEventStatus: operation=DiagnosticInfo_Motor_54.GetEventStatus
          SC_DiagnosticInfo_Etm_01_GetEventStatus: operation=DiagnosticInfo_Etm_01.GetEventStatus
  swc implementation NetIoMgr_Implementation: programming-language=C, sw-version=1.0.0, vendor-id=1, behavior=NetIoMgr_InternalBehavior
    code-descriptors:
      code Default: artifact-descriptors=autosar-engineering-object={short-label=DEFAULT, category=SWSRC}
